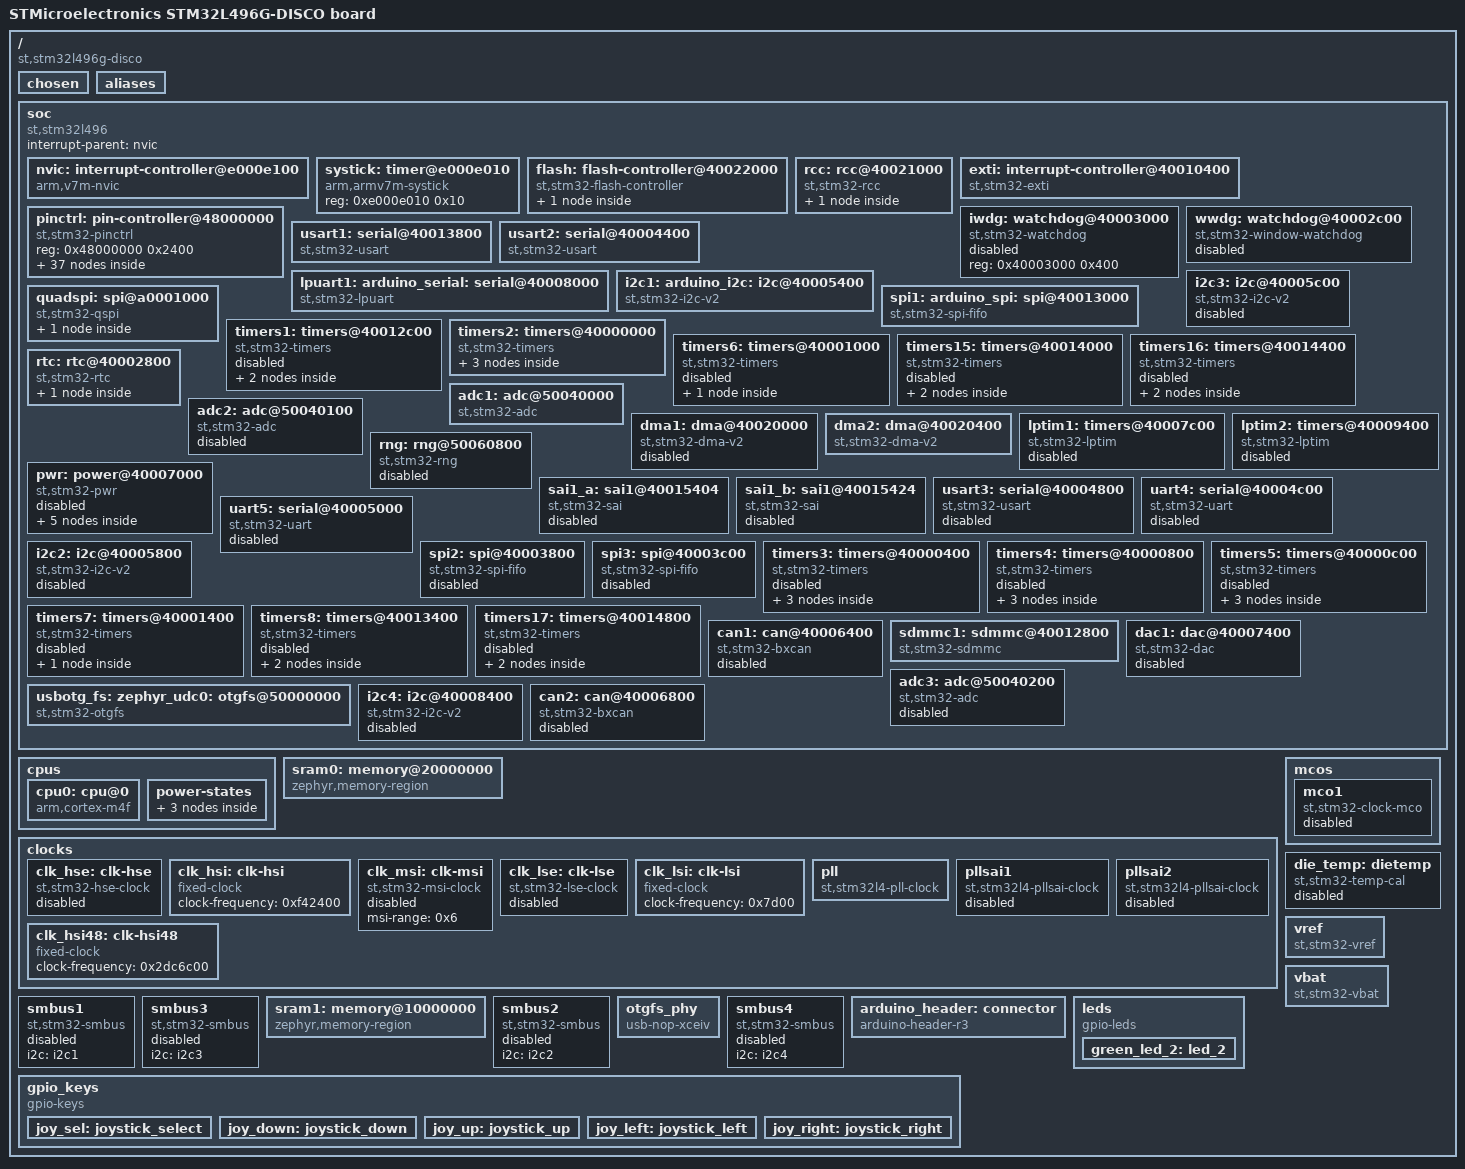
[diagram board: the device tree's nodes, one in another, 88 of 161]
/dts-v1/;

/* node '/' defined in zephyr/dts/common/skeleton.dtsi:9 */
/ {
	#address-cells = < 0x1 >;                            /* in zephyr/dts/common/skeleton.dtsi:10 */
	#size-cells = < 0x1 >;                               /* in zephyr/dts/common/skeleton.dtsi:11 */
	model = "STMicroelectronics STM32L496G-DISCO board"; /* in zephyr/boards/st/stm32l496g_disco/stm32l496g_disco.dts:14 */
	compatible = "st,stm32l496g-disco";                  /* in zephyr/boards/st/stm32l496g_disco/stm32l496g_disco.dts:15 */

	/* node '/chosen' defined in zephyr/dts/common/skeleton.dtsi:13 */
	chosen {
		zephyr,entropy = &rng;                /* in zephyr/dts/arm/st/l4/stm32l4.dtsi:26 */
		zephyr,console = &usart2;             /* in zephyr/boards/st/stm32l496g_disco/stm32l496g_disco.dts:18 */
		zephyr,shell-uart = &usart2;          /* in zephyr/boards/st/stm32l496g_disco/stm32l496g_disco.dts:19 */
		zephyr,sram = &sram0;                 /* in zephyr/boards/st/stm32l496g_disco/stm32l496g_disco.dts:20 */
		zephyr,flash = &flash0;               /* in zephyr/boards/st/stm32l496g_disco/stm32l496g_disco.dts:21 */
		zephyr,flash-controller = &mx25r6435; /* in zephyr/boards/st/stm32l496g_disco/stm32l496g_disco.dts:22 */
	};

	/* node '/aliases' defined in zephyr/dts/common/skeleton.dtsi:15 */
	aliases {
		led0 = &green_led_2;  /* in zephyr/boards/st/stm32l496g_disco/stm32l496g_disco.dts:69 */
		sw0 = &joy_sel;       /* in zephyr/boards/st/stm32l496g_disco/stm32l496g_disco.dts:70 */
		sw1 = &joy_down;      /* in zephyr/boards/st/stm32l496g_disco/stm32l496g_disco.dts:71 */
		sw2 = &joy_right;     /* in zephyr/boards/st/stm32l496g_disco/stm32l496g_disco.dts:72 */
		sw3 = &joy_up;        /* in zephyr/boards/st/stm32l496g_disco/stm32l496g_disco.dts:73 */
		sw4 = &joy_left;      /* in zephyr/boards/st/stm32l496g_disco/stm32l496g_disco.dts:74 */
		volt-sensor0 = &vref; /* in zephyr/boards/st/stm32l496g_disco/stm32l496g_disco.dts:75 */
		volt-sensor1 = &vbat; /* in zephyr/boards/st/stm32l496g_disco/stm32l496g_disco.dts:76 */
	};

	/* node '/soc' defined in zephyr/dts/arm/armv7-m.dtsi:6 */
	soc {
		#address-cells = < 0x1 >;     /* in zephyr/dts/arm/armv7-m.dtsi:7 */
		#size-cells = < 0x1 >;        /* in zephyr/dts/arm/armv7-m.dtsi:8 */
		interrupt-parent = < &nvic >; /* in zephyr/dts/arm/armv7-m.dtsi:10 */
		ranges;                       /* in zephyr/dts/arm/armv7-m.dtsi:11 */
		compatible = "st,stm32l496",
		             "st,stm32l4",
		             "simple-bus";    /* in zephyr/dts/arm/st/l4/stm32l496.dtsi:20 */

		/* node '/soc/interrupt-controller@e000e100' defined in zephyr/dts/arm/armv7-m.dtsi:13 */
		nvic: interrupt-controller@e000e100 {
			#address-cells = < 0x1 >;            /* in zephyr/dts/arm/armv7-m.dtsi:14 */
			compatible = "arm,v7m-nvic";         /* in zephyr/dts/arm/armv7-m.dtsi:15 */
			reg = < 0xe000e100 0xc00 >;          /* in zephyr/dts/arm/armv7-m.dtsi:16 */
			interrupt-controller;                /* in zephyr/dts/arm/armv7-m.dtsi:17 */
			#interrupt-cells = < 0x2 >;          /* in zephyr/dts/arm/armv7-m.dtsi:18 */
			arm,num-irq-priority-bits = < 0x4 >; /* in zephyr/dts/arm/st/l4/stm32l4.dtsi:596 */
			phandle = < 0x1 >;                   /* in zephyr/dts/arm/armv7-m.dtsi:10 */
		};

		/* node '/soc/timer@e000e010' defined in zephyr/dts/arm/armv7-m.dtsi:21 */
		systick: timer@e000e010 {
			compatible = "arm,armv7m-systick"; /* in zephyr/dts/arm/armv7-m.dtsi:22 */
			reg = < 0xe000e010 0x10 >;         /* in zephyr/dts/arm/armv7-m.dtsi:23 */
		};

		/* node '/soc/flash-controller@40022000' defined in zephyr/dts/arm/st/l4/stm32l4.dtsi:127 */
		flash: flash-controller@40022000 {
			compatible = "st,stm32-flash-controller",
			             "st,stm32l4-flash-controller"; /* in zephyr/dts/arm/st/l4/stm32l4.dtsi:128 */
			reg = < 0x40022000 0x400 >;                 /* in zephyr/dts/arm/st/l4/stm32l4.dtsi:129 */
			interrupts = < 0x4 0x0 >;                   /* in zephyr/dts/arm/st/l4/stm32l4.dtsi:130 */
			clocks = < &rcc 0x48 0x100 >;               /* in zephyr/dts/arm/st/l4/stm32l4.dtsi:131 */
			#address-cells = < 0x1 >;                   /* in zephyr/dts/arm/st/l4/stm32l4.dtsi:133 */
			#size-cells = < 0x1 >;                      /* in zephyr/dts/arm/st/l4/stm32l4.dtsi:134 */

			/* node '/soc/flash-controller@40022000/flash@8000000' defined in zephyr/dts/arm/st/l4/stm32l4.dtsi:136 */
			flash0: flash@8000000 {
				compatible = "st,stm32-nv-flash",
				             "soc-nv-flash";      /* in zephyr/dts/arm/st/l4/stm32l4.dtsi:137 */
				write-block-size = < 0x8 >;       /* in zephyr/dts/arm/st/l4/stm32l4.dtsi:139 */
				erase-block-size = < 0x800 >;     /* in zephyr/dts/arm/st/l4/stm32l4.dtsi:140 */
				max-erase-time = < 0x19 >;        /* in zephyr/dts/arm/st/l4/stm32l4.dtsi:142 */
				reg = < 0x8000000 0x100000 >;     /* in zephyr/dts/arm/st/l4/stm32l496Xg.dtsi:20 */
			};
		};

		/* node '/soc/rcc@40021000' defined in zephyr/dts/arm/st/l4/stm32l4.dtsi:146 */
		rcc: rcc@40021000 {
			compatible = "st,stm32-rcc";     /* in zephyr/dts/arm/st/l4/stm32l4.dtsi:147 */
			#clock-cells = < 0x2 >;          /* in zephyr/dts/arm/st/l4/stm32l4.dtsi:148 */
			reg = < 0x40021000 0x400 >;      /* in zephyr/dts/arm/st/l4/stm32l4.dtsi:149 */
			clocks = < &pll >;               /* in zephyr/boards/st/stm32l496g_disco/stm32l496g_disco.dts:103 */
			clock-frequency = < 0x4c4b400 >; /* in zephyr/boards/st/stm32l496g_disco/stm32l496g_disco.dts:104 */
			ahb-prescaler = < 0x1 >;         /* in zephyr/boards/st/stm32l496g_disco/stm32l496g_disco.dts:105 */
			apb1-prescaler = < 0x1 >;        /* in zephyr/boards/st/stm32l496g_disco/stm32l496g_disco.dts:106 */
			apb2-prescaler = < 0x1 >;        /* in zephyr/boards/st/stm32l496g_disco/stm32l496g_disco.dts:107 */
			phandle = < 0x2 >;               /* in zephyr/dts/arm/st/l4/stm32l4.dtsi:131 */

			/* node '/soc/rcc@40021000/reset-controller' defined in zephyr/dts/arm/st/l4/stm32l4.dtsi:151 */
			rctl: reset-controller {
				compatible = "st,stm32-rcc-rctl"; /* in zephyr/dts/arm/st/l4/stm32l4.dtsi:152 */
				#reset-cells = < 0x1 >;           /* in zephyr/dts/arm/st/l4/stm32l4.dtsi:153 */
				phandle = < 0x4 >;                /* in zephyr/dts/arm/st/l4/stm32l4.dtsi:230 */
			};
		};

		/* node '/soc/interrupt-controller@40010400' defined in zephyr/dts/arm/st/l4/stm32l4.dtsi:157 */
		exti: interrupt-controller@40010400 {
			compatible = "st,stm32-exti";  /* in zephyr/dts/arm/st/l4/stm32l4.dtsi:158 */
			interrupt-controller;          /* in zephyr/dts/arm/st/l4/stm32l4.dtsi:159 */
			#interrupt-cells = < 0x1 >;    /* in zephyr/dts/arm/st/l4/stm32l4.dtsi:160 */
			#address-cells = < 0x0 >;      /* in zephyr/dts/arm/st/l4/stm32l4.dtsi:161 */
			reg = < 0x40010400 0x400 >;    /* in zephyr/dts/arm/st/l4/stm32l4.dtsi:162 */
			clocks = < &rcc 0x60 0x1 >;    /* in zephyr/dts/arm/st/l4/stm32l4.dtsi:163 */
			num-lines = < 0x40 >;          /* in zephyr/dts/arm/st/l4/stm32l4.dtsi:164 */
			interrupts = < 0x6 0x0 >,
			             < 0x7 0x0 >,
			             < 0x8 0x0 >,
			             < 0x9 0x0 >,
			             < 0xa 0x0 >,
			             < 0x17 0x0 >,
			             < 0x28 0x0 >;     /* in zephyr/dts/arm/st/l4/stm32l4.dtsi:165 */
			interrupt-names = "line0",
			                  "line1",
			                  "line2",
			                  "line3",
			                  "line4",
			                  "line5-9",
			                  "line10-15"; /* in zephyr/dts/arm/st/l4/stm32l4.dtsi:167 */
			line-ranges = < 0x0 0x1 >,
			              < 0x1 0x1 >,
			              < 0x2 0x1 >,
			              < 0x3 0x1 >,
			              < 0x4 0x1 >,
			              < 0x5 0x5 >,
			              < 0xa 0x6 >;     /* in zephyr/dts/arm/st/l4/stm32l4.dtsi:169 */
		};

		/* node '/soc/pin-controller@48000000' defined in zephyr/dts/arm/st/l4/stm32l4.dtsi:173 */
		pinctrl: pin-controller@48000000 {
			compatible = "st,stm32-pinctrl"; /* in zephyr/dts/arm/st/l4/stm32l4.dtsi:174 */
			#address-cells = < 0x1 >;        /* in zephyr/dts/arm/st/l4/stm32l4.dtsi:175 */
			#size-cells = < 0x1 >;           /* in zephyr/dts/arm/st/l4/stm32l4.dtsi:176 */
			reg = < 0x48000000 0x2400 >;     /* in zephyr/dts/arm/st/l4/stm32l496.dtsi:40 */

			/* node '/soc/pin-controller@48000000/gpio@48000000' defined in zephyr/dts/arm/st/l4/stm32l4.dtsi:179 */
			gpioa: gpio@48000000 {
				compatible = "st,stm32-gpio"; /* in zephyr/dts/arm/st/l4/stm32l4.dtsi:180 */
				gpio-controller;              /* in zephyr/dts/arm/st/l4/stm32l4.dtsi:181 */
				#gpio-cells = < 0x2 >;        /* in zephyr/dts/arm/st/l4/stm32l4.dtsi:182 */
				reg = < 0x48000000 0x400 >;   /* in zephyr/dts/arm/st/l4/stm32l4.dtsi:183 */
				clocks = < &rcc 0x4c 0x1 >;   /* in zephyr/dts/arm/st/l4/stm32l4.dtsi:184 */
				phandle = < 0x17 >;           /* in zephyr/boards/st/stm32l496g_disco/stm32l496g_disco.dts:151 */
			};

			/* node '/soc/pin-controller@48000000/gpio@48000400' defined in zephyr/dts/arm/st/l4/stm32l4.dtsi:187 */
			gpiob: gpio@48000400 {
				compatible = "st,stm32-gpio"; /* in zephyr/dts/arm/st/l4/stm32l4.dtsi:188 */
				gpio-controller;              /* in zephyr/dts/arm/st/l4/stm32l4.dtsi:189 */
				#gpio-cells = < 0x2 >;        /* in zephyr/dts/arm/st/l4/stm32l4.dtsi:190 */
				reg = < 0x48000400 0x400 >;   /* in zephyr/dts/arm/st/l4/stm32l4.dtsi:191 */
				clocks = < &rcc 0x4c 0x2 >;   /* in zephyr/dts/arm/st/l4/stm32l4.dtsi:192 */
				phandle = < 0x32 >;           /* in zephyr/boards/st/stm32l496g_disco/arduino_r3_connector.dtsi:15 */
			};

			/* node '/soc/pin-controller@48000000/gpio@48000800' defined in zephyr/dts/arm/st/l4/stm32l4.dtsi:195 */
			gpioc: gpio@48000800 {
				compatible = "st,stm32-gpio"; /* in zephyr/dts/arm/st/l4/stm32l4.dtsi:196 */
				gpio-controller;              /* in zephyr/dts/arm/st/l4/stm32l4.dtsi:197 */
				#gpio-cells = < 0x2 >;        /* in zephyr/dts/arm/st/l4/stm32l4.dtsi:198 */
				reg = < 0x48000800 0x400 >;   /* in zephyr/dts/arm/st/l4/stm32l4.dtsi:199 */
				clocks = < &rcc 0x4c 0x4 >;   /* in zephyr/dts/arm/st/l4/stm32l4.dtsi:200 */
				phandle = < 0x2d >;           /* in zephyr/boards/st/stm32l496g_disco/arduino_r3_connector.dtsi:15 */
			};

			/* node '/soc/pin-controller@48000000/gpio@48001c00' defined in zephyr/dts/arm/st/l4/stm32l4.dtsi:203 */
			gpioh: gpio@48001c00 {
				compatible = "st,stm32-gpio"; /* in zephyr/dts/arm/st/l4/stm32l4.dtsi:204 */
				gpio-controller;              /* in zephyr/dts/arm/st/l4/stm32l4.dtsi:205 */
				#gpio-cells = < 0x2 >;        /* in zephyr/dts/arm/st/l4/stm32l4.dtsi:206 */
				reg = < 0x48001c00 0x400 >;   /* in zephyr/dts/arm/st/l4/stm32l4.dtsi:207 */
				clocks = < &rcc 0x4c 0x80 >;  /* in zephyr/dts/arm/st/l4/stm32l4.dtsi:208 */
				phandle = < 0x30 >;           /* in zephyr/boards/st/stm32l496g_disco/arduino_r3_connector.dtsi:15 */
			};

			/* node '/soc/pin-controller@48000000/gpio@48000c00' defined in zephyr/dts/arm/st/l4/stm32l471.dtsi:29 */
			gpiod: gpio@48000c00 {
				compatible = "st,stm32-gpio"; /* in zephyr/dts/arm/st/l4/stm32l471.dtsi:30 */
				gpio-controller;              /* in zephyr/dts/arm/st/l4/stm32l471.dtsi:31 */
				#gpio-cells = < 0x2 >;        /* in zephyr/dts/arm/st/l4/stm32l471.dtsi:32 */
				reg = < 0x48000c00 0x400 >;   /* in zephyr/dts/arm/st/l4/stm32l471.dtsi:33 */
				clocks = < &rcc 0x4c 0x8 >;   /* in zephyr/dts/arm/st/l4/stm32l471.dtsi:34 */
			};

			/* node '/soc/pin-controller@48000000/gpio@48001000' defined in zephyr/dts/arm/st/l4/stm32l471.dtsi:37 */
			gpioe: gpio@48001000 {
				compatible = "st,stm32-gpio"; /* in zephyr/dts/arm/st/l4/stm32l471.dtsi:38 */
				gpio-controller;              /* in zephyr/dts/arm/st/l4/stm32l471.dtsi:39 */
				#gpio-cells = < 0x2 >;        /* in zephyr/dts/arm/st/l4/stm32l471.dtsi:40 */
				reg = < 0x48001000 0x400 >;   /* in zephyr/dts/arm/st/l4/stm32l471.dtsi:41 */
				clocks = < &rcc 0x4c 0x10 >;  /* in zephyr/dts/arm/st/l4/stm32l471.dtsi:42 */
			};

			/* node '/soc/pin-controller@48000000/gpio@48001400' defined in zephyr/dts/arm/st/l4/stm32l471.dtsi:45 */
			gpiof: gpio@48001400 {
				compatible = "st,stm32-gpio"; /* in zephyr/dts/arm/st/l4/stm32l471.dtsi:46 */
				gpio-controller;              /* in zephyr/dts/arm/st/l4/stm32l471.dtsi:47 */
				#gpio-cells = < 0x2 >;        /* in zephyr/dts/arm/st/l4/stm32l471.dtsi:48 */
				reg = < 0x48001400 0x400 >;   /* in zephyr/dts/arm/st/l4/stm32l471.dtsi:49 */
				clocks = < &rcc 0x4c 0x20 >;  /* in zephyr/dts/arm/st/l4/stm32l471.dtsi:50 */
				phandle = < 0x2e >;           /* in zephyr/boards/st/stm32l496g_disco/arduino_r3_connector.dtsi:15 */
			};

			/* node '/soc/pin-controller@48000000/gpio@48001800' defined in zephyr/dts/arm/st/l4/stm32l471.dtsi:53 */
			gpiog: gpio@48001800 {
				compatible = "st,stm32-gpio"; /* in zephyr/dts/arm/st/l4/stm32l471.dtsi:54 */
				gpio-controller;              /* in zephyr/dts/arm/st/l4/stm32l471.dtsi:55 */
				#gpio-cells = < 0x2 >;        /* in zephyr/dts/arm/st/l4/stm32l471.dtsi:56 */
				reg = < 0x48001800 0x400 >;   /* in zephyr/dts/arm/st/l4/stm32l471.dtsi:57 */
				clocks = < &rcc 0x4c 0x40 >;  /* in zephyr/dts/arm/st/l4/stm32l471.dtsi:58 */
				phandle = < 0x2f >;           /* in zephyr/boards/st/stm32l496g_disco/arduino_r3_connector.dtsi:15 */
			};

			/* node '/soc/pin-controller@48000000/gpio@48002000' defined in zephyr/dts/arm/st/l4/stm32l496.dtsi:42 */
			gpioi: gpio@48002000 {
				compatible = "st,stm32-gpio"; /* in zephyr/dts/arm/st/l4/stm32l496.dtsi:43 */
				gpio-controller;              /* in zephyr/dts/arm/st/l4/stm32l496.dtsi:44 */
				#gpio-cells = < 0x2 >;        /* in zephyr/dts/arm/st/l4/stm32l496.dtsi:45 */
				ngpios = < 0xc >;             /* in zephyr/dts/arm/st/l4/stm32l496.dtsi:46 */
				reg = < 0x48002000 0x400 >;   /* in zephyr/dts/arm/st/l4/stm32l496.dtsi:47 */
				clocks = < &rcc 0x4c 0x100 >; /* in zephyr/dts/arm/st/l4/stm32l496.dtsi:48 */
				phandle = < 0x31 >;           /* in zephyr/boards/st/stm32l496g_disco/arduino_r3_connector.dtsi:15 */
			};

			/* node '/soc/pin-controller@48000000/adc1_in2_pc1' defined in modules/hal/stm32/dts/st/l4/stm32l496a(e-g)ix-pinctrl.dtsi:59 */
			adc1_in2_pc1: adc1_in2_pc1 {
				pinmux = < 0x430 >; /* in modules/hal/stm32/dts/st/l4/stm32l496a(e-g)ix-pinctrl.dtsi:60 */
				phandle = < 0x19 >; /* in zephyr/boards/st/stm32l496g_disco/stm32l496g_disco.dts:171 */
			};

			/* node '/soc/pin-controller@48000000/i2c1_scl_pb8' defined in modules/hal/stm32/dts/st/l4/stm32l496a(e-g)ix-pinctrl.dtsi:1612 */
			i2c1_scl_pb8: i2c1_scl_pb8 {
				pinmux = < 0x304 >; /* in modules/hal/stm32/dts/st/l4/stm32l496a(e-g)ix-pinctrl.dtsi:1613 */
				bias-pull-up;       /* in modules/hal/stm32/dts/st/l4/stm32l496a(e-g)ix-pinctrl.dtsi:1614 */
				drive-open-drain;   /* in modules/hal/stm32/dts/st/l4/stm32l496a(e-g)ix-pinctrl.dtsi:1615 */
				phandle = < 0xb >;  /* in zephyr/boards/st/stm32l496g_disco/stm32l496g_disco.dts:142 */
			};

			/* node '/soc/pin-controller@48000000/i2c1_sda_pb7' defined in modules/hal/stm32/dts/st/l4/stm32l496a(e-g)ix-pinctrl.dtsi:1704 */
			i2c1_sda_pb7: i2c1_sda_pb7 {
				pinmux = < 0x2e4 >; /* in modules/hal/stm32/dts/st/l4/stm32l496a(e-g)ix-pinctrl.dtsi:1705 */
				bias-pull-up;       /* in modules/hal/stm32/dts/st/l4/stm32l496a(e-g)ix-pinctrl.dtsi:1706 */
				drive-open-drain;   /* in modules/hal/stm32/dts/st/l4/stm32l496a(e-g)ix-pinctrl.dtsi:1707 */
				phandle = < 0xc >;  /* in zephyr/boards/st/stm32l496g_disco/stm32l496g_disco.dts:142 */
			};

			/* node '/soc/pin-controller@48000000/quadspi_clk_pa3' defined in modules/hal/stm32/dts/st/l4/stm32l496a(e-g)ix-pinctrl.dtsi:1920 */
			quadspi_clk_pa3: quadspi_clk_pa3 {
				pinmux = < 0x6a >;             /* in modules/hal/stm32/dts/st/l4/stm32l496a(e-g)ix-pinctrl.dtsi:1921 */
				slew-rate = "very-high-speed"; /* in modules/hal/stm32/dts/st/l4/stm32l496a(e-g)ix-pinctrl.dtsi:1922 */
				phandle = < 0x12 >;            /* in zephyr/boards/st/stm32l496g_disco/stm32l496g_disco.dts:198 */
			};

			/* node '/soc/pin-controller@48000000/quadspi_bk1_io3_pa6' defined in modules/hal/stm32/dts/st/l4/stm32l496a(e-g)ix-pinctrl.dtsi:1925 */
			quadspi_bk1_io3_pa6: quadspi_bk1_io3_pa6 {
				pinmux = < 0xca >;             /* in modules/hal/stm32/dts/st/l4/stm32l496a(e-g)ix-pinctrl.dtsi:1926 */
				slew-rate = "very-high-speed"; /* in modules/hal/stm32/dts/st/l4/stm32l496a(e-g)ix-pinctrl.dtsi:1927 */
				phandle = < 0x10 >;            /* in zephyr/boards/st/stm32l496g_disco/stm32l496g_disco.dts:198 */
			};

			/* node '/soc/pin-controller@48000000/quadspi_bk1_io2_pa7' defined in modules/hal/stm32/dts/st/l4/stm32l496a(e-g)ix-pinctrl.dtsi:1930 */
			quadspi_bk1_io2_pa7: quadspi_bk1_io2_pa7 {
				pinmux = < 0xea >;             /* in modules/hal/stm32/dts/st/l4/stm32l496a(e-g)ix-pinctrl.dtsi:1931 */
				slew-rate = "very-high-speed"; /* in modules/hal/stm32/dts/st/l4/stm32l496a(e-g)ix-pinctrl.dtsi:1932 */
				phandle = < 0xf >;             /* in zephyr/boards/st/stm32l496g_disco/stm32l496g_disco.dts:198 */
			};

			/* node '/soc/pin-controller@48000000/quadspi_bk1_io1_pb0' defined in modules/hal/stm32/dts/st/l4/stm32l496a(e-g)ix-pinctrl.dtsi:1935 */
			quadspi_bk1_io1_pb0: quadspi_bk1_io1_pb0 {
				pinmux = < 0x20a >;            /* in modules/hal/stm32/dts/st/l4/stm32l496a(e-g)ix-pinctrl.dtsi:1936 */
				slew-rate = "very-high-speed"; /* in modules/hal/stm32/dts/st/l4/stm32l496a(e-g)ix-pinctrl.dtsi:1937 */
				phandle = < 0xe >;             /* in zephyr/boards/st/stm32l496g_disco/stm32l496g_disco.dts:198 */
			};

			/* node '/soc/pin-controller@48000000/quadspi_bk1_io0_pb1' defined in modules/hal/stm32/dts/st/l4/stm32l496a(e-g)ix-pinctrl.dtsi:1940 */
			quadspi_bk1_io0_pb1: quadspi_bk1_io0_pb1 {
				pinmux = < 0x22a >;            /* in modules/hal/stm32/dts/st/l4/stm32l496a(e-g)ix-pinctrl.dtsi:1941 */
				slew-rate = "very-high-speed"; /* in modules/hal/stm32/dts/st/l4/stm32l496a(e-g)ix-pinctrl.dtsi:1942 */
				phandle = < 0xd >;             /* in zephyr/boards/st/stm32l496g_disco/stm32l496g_disco.dts:198 */
			};

			/* node '/soc/pin-controller@48000000/quadspi_bk1_ncs_pb11' defined in modules/hal/stm32/dts/st/l4/stm32l496a(e-g)ix-pinctrl.dtsi:1950 */
			quadspi_bk1_ncs_pb11: quadspi_bk1_ncs_pb11 {
				pinmux = < 0x36a >;            /* in modules/hal/stm32/dts/st/l4/stm32l496a(e-g)ix-pinctrl.dtsi:1951 */
				slew-rate = "very-high-speed"; /* in modules/hal/stm32/dts/st/l4/stm32l496a(e-g)ix-pinctrl.dtsi:1952 */
				phandle = < 0x11 >;            /* in zephyr/boards/st/stm32l496g_disco/stm32l496g_disco.dts:198 */
			};

			/* node '/soc/pin-controller@48000000/sdmmc1_d0_pc8' defined in modules/hal/stm32/dts/st/l4/stm32l496a(e-g)ix-pinctrl.dtsi:2297 */
			sdmmc1_d0_pc8: sdmmc1_d0_pc8 {
				pinmux = < 0x50c >;            /* in modules/hal/stm32/dts/st/l4/stm32l496a(e-g)ix-pinctrl.dtsi:2298 */
				bias-pull-up;                  /* in modules/hal/stm32/dts/st/l4/stm32l496a(e-g)ix-pinctrl.dtsi:2299 */
				slew-rate = "very-high-speed"; /* in modules/hal/stm32/dts/st/l4/stm32l496a(e-g)ix-pinctrl.dtsi:2300 */
				phandle = < 0x1a >;            /* in zephyr/boards/st/stm32l496g_disco/stm32l496g_disco.dts:162 */
			};

			/* node '/soc/pin-controller@48000000/sdmmc1_d1_pc9' defined in modules/hal/stm32/dts/st/l4/stm32l496a(e-g)ix-pinctrl.dtsi:2303 */
			sdmmc1_d1_pc9: sdmmc1_d1_pc9 {
				pinmux = < 0x52c >;            /* in modules/hal/stm32/dts/st/l4/stm32l496a(e-g)ix-pinctrl.dtsi:2304 */
				bias-pull-up;                  /* in modules/hal/stm32/dts/st/l4/stm32l496a(e-g)ix-pinctrl.dtsi:2305 */
				slew-rate = "very-high-speed"; /* in modules/hal/stm32/dts/st/l4/stm32l496a(e-g)ix-pinctrl.dtsi:2306 */
				phandle = < 0x1b >;            /* in zephyr/boards/st/stm32l496g_disco/stm32l496g_disco.dts:162 */
			};

			/* node '/soc/pin-controller@48000000/sdmmc1_d2_pc10' defined in modules/hal/stm32/dts/st/l4/stm32l496a(e-g)ix-pinctrl.dtsi:2309 */
			sdmmc1_d2_pc10: sdmmc1_d2_pc10 {
				pinmux = < 0x54c >;            /* in modules/hal/stm32/dts/st/l4/stm32l496a(e-g)ix-pinctrl.dtsi:2310 */
				bias-pull-up;                  /* in modules/hal/stm32/dts/st/l4/stm32l496a(e-g)ix-pinctrl.dtsi:2311 */
				slew-rate = "very-high-speed"; /* in modules/hal/stm32/dts/st/l4/stm32l496a(e-g)ix-pinctrl.dtsi:2312 */
				phandle = < 0x1c >;            /* in zephyr/boards/st/stm32l496g_disco/stm32l496g_disco.dts:162 */
			};

			/* node '/soc/pin-controller@48000000/sdmmc1_d3_pc11' defined in modules/hal/stm32/dts/st/l4/stm32l496a(e-g)ix-pinctrl.dtsi:2315 */
			sdmmc1_d3_pc11: sdmmc1_d3_pc11 {
				pinmux = < 0x56c >;            /* in modules/hal/stm32/dts/st/l4/stm32l496a(e-g)ix-pinctrl.dtsi:2316 */
				bias-pull-up;                  /* in modules/hal/stm32/dts/st/l4/stm32l496a(e-g)ix-pinctrl.dtsi:2317 */
				slew-rate = "very-high-speed"; /* in modules/hal/stm32/dts/st/l4/stm32l496a(e-g)ix-pinctrl.dtsi:2318 */
				phandle = < 0x1d >;            /* in zephyr/boards/st/stm32l496g_disco/stm32l496g_disco.dts:162 */
			};

			/* node '/soc/pin-controller@48000000/sdmmc1_ck_pc12' defined in modules/hal/stm32/dts/st/l4/stm32l496a(e-g)ix-pinctrl.dtsi:2321 */
			sdmmc1_ck_pc12: sdmmc1_ck_pc12 {
				pinmux = < 0x58c >;            /* in modules/hal/stm32/dts/st/l4/stm32l496a(e-g)ix-pinctrl.dtsi:2322 */
				bias-pull-up;                  /* in modules/hal/stm32/dts/st/l4/stm32l496a(e-g)ix-pinctrl.dtsi:2323 */
				slew-rate = "very-high-speed"; /* in modules/hal/stm32/dts/st/l4/stm32l496a(e-g)ix-pinctrl.dtsi:2324 */
				phandle = < 0x1e >;            /* in zephyr/boards/st/stm32l496g_disco/stm32l496g_disco.dts:162 */
			};

			/* node '/soc/pin-controller@48000000/sdmmc1_cmd_pd2' defined in modules/hal/stm32/dts/st/l4/stm32l496a(e-g)ix-pinctrl.dtsi:2327 */
			sdmmc1_cmd_pd2: sdmmc1_cmd_pd2 {
				pinmux = < 0x64c >;            /* in modules/hal/stm32/dts/st/l4/stm32l496a(e-g)ix-pinctrl.dtsi:2328 */
				bias-pull-up;                  /* in modules/hal/stm32/dts/st/l4/stm32l496a(e-g)ix-pinctrl.dtsi:2329 */
				slew-rate = "very-high-speed"; /* in modules/hal/stm32/dts/st/l4/stm32l496a(e-g)ix-pinctrl.dtsi:2330 */
				phandle = < 0x1f >;            /* in zephyr/boards/st/stm32l496g_disco/stm32l496g_disco.dts:162 */
			};

			/* node '/soc/pin-controller@48000000/spi1_miso_pb4' defined in modules/hal/stm32/dts/st/l4/stm32l496a(e-g)ix-pinctrl.dtsi:2345 */
			spi1_miso_pb4: spi1_miso_pb4 {
				pinmux = < 0x285 >; /* in modules/hal/stm32/dts/st/l4/stm32l496a(e-g)ix-pinctrl.dtsi:2346 */
				bias-pull-down;     /* in modules/hal/stm32/dts/st/l4/stm32l496a(e-g)ix-pinctrl.dtsi:2347 */
				phandle = < 0x15 >; /* in zephyr/boards/st/stm32l496g_disco/stm32l496g_disco.dts:149 */
			};

			/* node '/soc/pin-controller@48000000/spi1_mosi_pb5' defined in modules/hal/stm32/dts/st/l4/stm32l496a(e-g)ix-pinctrl.dtsi:2407 */
			spi1_mosi_pb5: spi1_mosi_pb5 {
				pinmux = < 0x2a5 >; /* in modules/hal/stm32/dts/st/l4/stm32l496a(e-g)ix-pinctrl.dtsi:2408 */
				bias-pull-down;     /* in modules/hal/stm32/dts/st/l4/stm32l496a(e-g)ix-pinctrl.dtsi:2409 */
				phandle = < 0x16 >; /* in zephyr/boards/st/stm32l496g_disco/stm32l496g_disco.dts:149 */
			};

			/* node '/soc/pin-controller@48000000/spi1_sck_pa5' defined in modules/hal/stm32/dts/st/l4/stm32l496a(e-g)ix-pinctrl.dtsi:2532 */
			spi1_sck_pa5: spi1_sck_pa5 {
				pinmux = < 0xa5 >;             /* in modules/hal/stm32/dts/st/l4/stm32l496a(e-g)ix-pinctrl.dtsi:2533 */
				bias-pull-down;                /* in modules/hal/stm32/dts/st/l4/stm32l496a(e-g)ix-pinctrl.dtsi:2534 */
				slew-rate = "very-high-speed"; /* in modules/hal/stm32/dts/st/l4/stm32l496a(e-g)ix-pinctrl.dtsi:2535 */
				phandle = < 0x14 >;            /* in zephyr/boards/st/stm32l496g_disco/stm32l496g_disco.dts:149 */
			};

			/* node '/soc/pin-controller@48000000/tim2_ch1_pa0' defined in modules/hal/stm32/dts/st/l4/stm32l496a(e-g)ix-pinctrl.dtsi:2742 */
			tim2_ch1_pa0: tim2_ch1_pa0 {
				pinmux = < 0x1 >;   /* in modules/hal/stm32/dts/st/l4/stm32l496a(e-g)ix-pinctrl.dtsi:2743 */
				phandle = < 0x18 >; /* in zephyr/boards/st/stm32l496g_disco/stm32l496g_disco.dts:136 */
			};

			/* node '/soc/pin-controller@48000000/lpuart1_rx_pg8' defined in modules/hal/stm32/dts/st/l4/stm32l496a(e-g)ix-pinctrl.dtsi:3419 */
			lpuart1_rx_pg8: lpuart1_rx_pg8 {
				pinmux = < 0xd08 >; /* in modules/hal/stm32/dts/st/l4/stm32l496a(e-g)ix-pinctrl.dtsi:3420 */
				phandle = < 0xa >;  /* in zephyr/boards/st/stm32l496g_disco/stm32l496g_disco.dts:125 */
			};

			/* node '/soc/pin-controller@48000000/usart1_rx_pg10' defined in modules/hal/stm32/dts/st/l4/stm32l496a(e-g)ix-pinctrl.dtsi:3423 */
			usart1_rx_pg10: usart1_rx_pg10 {
				pinmux = < 0xd47 >; /* in modules/hal/stm32/dts/st/l4/stm32l496a(e-g)ix-pinctrl.dtsi:3424 */
				phandle = < 0x6 >;  /* in zephyr/boards/st/stm32l496g_disco/stm32l496g_disco.dts:111 */
			};

			/* node '/soc/pin-controller@48000000/usart2_rx_pd6' defined in modules/hal/stm32/dts/st/l4/stm32l496a(e-g)ix-pinctrl.dtsi:3435 */
			usart2_rx_pd6: usart2_rx_pd6 {
				pinmux = < 0x6c7 >; /* in modules/hal/stm32/dts/st/l4/stm32l496a(e-g)ix-pinctrl.dtsi:3436 */
				phandle = < 0x8 >;  /* in zephyr/boards/st/stm32l496g_disco/stm32l496g_disco.dts:118 */
			};

			/* node '/soc/pin-controller@48000000/usart1_tx_pb6' defined in modules/hal/stm32/dts/st/l4/stm32l496a(e-g)ix-pinctrl.dtsi:3479 */
			usart1_tx_pb6: usart1_tx_pb6 {
				pinmux = < 0x2c7 >; /* in modules/hal/stm32/dts/st/l4/stm32l496a(e-g)ix-pinctrl.dtsi:3480 */
				bias-pull-up;       /* in modules/hal/stm32/dts/st/l4/stm32l496a(e-g)ix-pinctrl.dtsi:3481 */
				phandle = < 0x5 >;  /* in zephyr/boards/st/stm32l496g_disco/stm32l496g_disco.dts:111 */
			};

			/* node '/soc/pin-controller@48000000/lpuart1_tx_pg7' defined in modules/hal/stm32/dts/st/l4/stm32l496a(e-g)ix-pinctrl.dtsi:3494 */
			lpuart1_tx_pg7: lpuart1_tx_pg7 {
				pinmux = < 0xce8 >; /* in modules/hal/stm32/dts/st/l4/stm32l496a(e-g)ix-pinctrl.dtsi:3495 */
				bias-pull-up;       /* in modules/hal/stm32/dts/st/l4/stm32l496a(e-g)ix-pinctrl.dtsi:3496 */
				phandle = < 0x9 >;  /* in zephyr/boards/st/stm32l496g_disco/stm32l496g_disco.dts:125 */
			};

			/* node '/soc/pin-controller@48000000/usart2_tx_pa2' defined in modules/hal/stm32/dts/st/l4/stm32l496a(e-g)ix-pinctrl.dtsi:3504 */
			usart2_tx_pa2: usart2_tx_pa2 {
				pinmux = < 0x47 >; /* in modules/hal/stm32/dts/st/l4/stm32l496a(e-g)ix-pinctrl.dtsi:3505 */
				bias-pull-up;      /* in modules/hal/stm32/dts/st/l4/stm32l496a(e-g)ix-pinctrl.dtsi:3506 */
				phandle = < 0x7 >; /* in zephyr/boards/st/stm32l496g_disco/stm32l496g_disco.dts:118 */
			};

			/* node '/soc/pin-controller@48000000/usb_otg_fs_id_pa10' defined in modules/hal/stm32/dts/st/l4/stm32l496a(e-g)ix-pinctrl.dtsi:3559 */
			usb_otg_fs_id_pa10: usb_otg_fs_id_pa10 {
				pinmux = < 0x14a >; /* in modules/hal/stm32/dts/st/l4/stm32l496a(e-g)ix-pinctrl.dtsi:3560 */
				phandle = < 0x23 >; /* in zephyr/boards/st/stm32l496g_disco/stm32l496g_disco.dts:179 */
			};

			/* node '/soc/pin-controller@48000000/usb_otg_fs_dm_pa11' defined in modules/hal/stm32/dts/st/l4/stm32l496a(e-g)ix-pinctrl.dtsi:3563 */
			usb_otg_fs_dm_pa11: usb_otg_fs_dm_pa11 {
				pinmux = < 0x16a >; /* in modules/hal/stm32/dts/st/l4/stm32l496a(e-g)ix-pinctrl.dtsi:3564 */
				phandle = < 0x21 >; /* in zephyr/boards/st/stm32l496g_disco/stm32l496g_disco.dts:179 */
			};

			/* node '/soc/pin-controller@48000000/usb_otg_fs_dp_pa12' defined in modules/hal/stm32/dts/st/l4/stm32l496a(e-g)ix-pinctrl.dtsi:3567 */
			usb_otg_fs_dp_pa12: usb_otg_fs_dp_pa12 {
				pinmux = < 0x18a >; /* in modules/hal/stm32/dts/st/l4/stm32l496a(e-g)ix-pinctrl.dtsi:3568 */
				phandle = < 0x22 >; /* in zephyr/boards/st/stm32l496g_disco/stm32l496g_disco.dts:179 */
			};
		};

		/* node '/soc/watchdog@40003000' defined in zephyr/dts/arm/st/l4/stm32l4.dtsi:212 */
		iwdg: watchdog@40003000 {
			compatible = "st,stm32-watchdog"; /* in zephyr/dts/arm/st/l4/stm32l4.dtsi:213 */
			reg = < 0x40003000 0x400 >;       /* in zephyr/dts/arm/st/l4/stm32l4.dtsi:214 */
			status = "disabled";              /* in zephyr/dts/arm/st/l4/stm32l4.dtsi:215 */
		};

		/* node '/soc/watchdog@40002c00' defined in zephyr/dts/arm/st/l4/stm32l4.dtsi:218 */
		wwdg: watchdog@40002c00 {
			compatible = "st,stm32-window-watchdog"; /* in zephyr/dts/arm/st/l4/stm32l4.dtsi:219 */
			reg = < 0x40002c00 0x400 >;              /* in zephyr/dts/arm/st/l4/stm32l4.dtsi:220 */
			clocks = < &rcc 0x58 0x800 >;            /* in zephyr/dts/arm/st/l4/stm32l4.dtsi:221 */
			interrupts = < 0x0 0x7 >;                /* in zephyr/dts/arm/st/l4/stm32l4.dtsi:222 */
			status = "disabled";                     /* in zephyr/dts/arm/st/l4/stm32l4.dtsi:223 */
		};

		/* node '/soc/serial@40013800' defined in zephyr/dts/arm/st/l4/stm32l4.dtsi:226 */
		usart1: serial@40013800 {
			compatible = "st,stm32-usart",
			             "st,stm32-uart";                   /* in zephyr/dts/arm/st/l4/stm32l4.dtsi:227 */
			reg = < 0x40013800 0x400 >;                     /* in zephyr/dts/arm/st/l4/stm32l4.dtsi:228 */
			clocks = < &rcc 0x60 0x4000 >;                  /* in zephyr/dts/arm/st/l4/stm32l4.dtsi:229 */
			resets = < &rctl 0x80e >;                       /* in zephyr/dts/arm/st/l4/stm32l4.dtsi:230 */
			interrupts = < 0x25 0x0 >;                      /* in zephyr/dts/arm/st/l4/stm32l4.dtsi:231 */
			pinctrl-0 = < &usart1_tx_pb6 &usart1_rx_pg10 >; /* in zephyr/boards/st/stm32l496g_disco/stm32l496g_disco.dts:111 */
			pinctrl-names = "default";                      /* in zephyr/boards/st/stm32l496g_disco/stm32l496g_disco.dts:112 */
			current-speed = < 0x1c200 >;                    /* in zephyr/boards/st/stm32l496g_disco/stm32l496g_disco.dts:113 */
			status = "okay";                                /* in zephyr/boards/st/stm32l496g_disco/stm32l496g_disco.dts:114 */
		};

		/* node '/soc/serial@40004400' defined in zephyr/dts/arm/st/l4/stm32l4.dtsi:235 */
		usart2: serial@40004400 {
			compatible = "st,stm32-usart",
			             "st,stm32-uart";                  /* in zephyr/dts/arm/st/l4/stm32l4.dtsi:236 */
			reg = < 0x40004400 0x400 >;                    /* in zephyr/dts/arm/st/l4/stm32l4.dtsi:237 */
			clocks = < &rcc 0x58 0x20000 >;                /* in zephyr/dts/arm/st/l4/stm32l4.dtsi:238 */
			resets = < &rctl 0x711 >;                      /* in zephyr/dts/arm/st/l4/stm32l4.dtsi:239 */
			interrupts = < 0x26 0x0 >;                     /* in zephyr/dts/arm/st/l4/stm32l4.dtsi:240 */
			pinctrl-0 = < &usart2_tx_pa2 &usart2_rx_pd6 >; /* in zephyr/boards/st/stm32l496g_disco/stm32l496g_disco.dts:118 */
			pinctrl-names = "default";                     /* in zephyr/boards/st/stm32l496g_disco/stm32l496g_disco.dts:119 */
			current-speed = < 0x1c200 >;                   /* in zephyr/boards/st/stm32l496g_disco/stm32l496g_disco.dts:120 */
			status = "okay";                               /* in zephyr/boards/st/stm32l496g_disco/stm32l496g_disco.dts:121 */
		};

		/* node '/soc/serial@40008000' defined in zephyr/dts/arm/st/l4/stm32l4.dtsi:244 */
		lpuart1: arduino_serial: serial@40008000 {
			compatible = "st,stm32-lpuart",
			             "st,stm32-uart";                    /* in zephyr/dts/arm/st/l4/stm32l4.dtsi:245 */
			reg = < 0x40008000 0x400 >;                      /* in zephyr/dts/arm/st/l4/stm32l4.dtsi:246 */
			clocks = < &rcc 0x5c 0x1 >;                      /* in zephyr/dts/arm/st/l4/stm32l4.dtsi:247 */
			resets = < &rctl 0x780 >;                        /* in zephyr/dts/arm/st/l4/stm32l4.dtsi:248 */
			interrupts = < 0x46 0x0 >;                       /* in zephyr/dts/arm/st/l4/stm32l4.dtsi:249 */
			pinctrl-0 = < &lpuart1_tx_pg7 &lpuart1_rx_pg8 >; /* in zephyr/boards/st/stm32l496g_disco/stm32l496g_disco.dts:125 */
			pinctrl-names = "default";                       /* in zephyr/boards/st/stm32l496g_disco/stm32l496g_disco.dts:126 */
			current-speed = < 0x1c200 >;                     /* in zephyr/boards/st/stm32l496g_disco/stm32l496g_disco.dts:127 */
			status = "okay";                                 /* in zephyr/boards/st/stm32l496g_disco/stm32l496g_disco.dts:128 */
		};

		/* node '/soc/i2c@40005400' defined in zephyr/dts/arm/st/l4/stm32l4.dtsi:253 */
		i2c1: arduino_i2c: i2c@40005400 {
			compatible = "st,stm32-i2c-v2";              /* in zephyr/dts/arm/st/l4/stm32l4.dtsi:254 */
			#address-cells = < 0x1 >;                    /* in zephyr/dts/arm/st/l4/stm32l4.dtsi:256 */
			#size-cells = < 0x0 >;                       /* in zephyr/dts/arm/st/l4/stm32l4.dtsi:257 */
			reg = < 0x40005400 0x400 >;                  /* in zephyr/dts/arm/st/l4/stm32l4.dtsi:258 */
			clocks = < &rcc 0x58 0x200000 >;             /* in zephyr/dts/arm/st/l4/stm32l4.dtsi:259 */
			interrupts = < 0x1f 0x0 >,
			             < 0x20 0x0 >;                   /* in zephyr/dts/arm/st/l4/stm32l4.dtsi:260 */
			interrupt-names = "event",
			                  "error";                   /* in zephyr/dts/arm/st/l4/stm32l4.dtsi:261 */
			pinctrl-0 = < &i2c1_scl_pb8 &i2c1_sda_pb7 >; /* in zephyr/boards/st/stm32l496g_disco/stm32l496g_disco.dts:142 */
			pinctrl-names = "default";                   /* in zephyr/boards/st/stm32l496g_disco/stm32l496g_disco.dts:143 */
			status = "okay";                             /* in zephyr/boards/st/stm32l496g_disco/stm32l496g_disco.dts:144 */
			clock-frequency = < 0x61a80 >;               /* in zephyr/boards/st/stm32l496g_disco/stm32l496g_disco.dts:145 */
			phandle = < 0x29 >;                          /* in zephyr/dts/arm/st/l4/stm32l4.dtsi:582 */
		};

		/* node '/soc/i2c@40005c00' defined in zephyr/dts/arm/st/l4/stm32l4.dtsi:265 */
		i2c3: i2c@40005c00 {
			compatible = "st,stm32-i2c-v2";  /* in zephyr/dts/arm/st/l4/stm32l4.dtsi:266 */
			clock-frequency = < 0x186a0 >;   /* in zephyr/dts/arm/st/l4/stm32l4.dtsi:267 */
			#address-cells = < 0x1 >;        /* in zephyr/dts/arm/st/l4/stm32l4.dtsi:268 */
			#size-cells = < 0x0 >;           /* in zephyr/dts/arm/st/l4/stm32l4.dtsi:269 */
			reg = < 0x40005c00 0x400 >;      /* in zephyr/dts/arm/st/l4/stm32l4.dtsi:270 */
			clocks = < &rcc 0x58 0x800000 >; /* in zephyr/dts/arm/st/l4/stm32l4.dtsi:271 */
			interrupts = < 0x48 0x0 >,
			             < 0x49 0x0 >;       /* in zephyr/dts/arm/st/l4/stm32l4.dtsi:272 */
			interrupt-names = "event",
			                  "error";       /* in zephyr/dts/arm/st/l4/stm32l4.dtsi:273 */
			status = "disabled";             /* in zephyr/dts/arm/st/l4/stm32l4.dtsi:274 */
			phandle = < 0x2a >;              /* in zephyr/dts/arm/st/l4/stm32l4.dtsi:590 */
		};

		/* node '/soc/spi@a0001000' defined in zephyr/dts/arm/st/l4/stm32l4.dtsi:277 */
		quadspi: spi@a0001000 {
			compatible = "st,stm32-qspi";                                                                     /* in zephyr/dts/arm/st/l4/stm32l4.dtsi:278 */
			#address-cells = < 0x1 >;                                                                         /* in zephyr/dts/arm/st/l4/stm32l4.dtsi:279 */
			#size-cells = < 0x0 >;                                                                            /* in zephyr/dts/arm/st/l4/stm32l4.dtsi:280 */
			reg = < 0xa0001000 0x400 >,
			      < 0x90000000 0x10000000 >;                                                                  /* in zephyr/dts/arm/st/l4/stm32l4.dtsi:281 */
			interrupts = < 0x47 0x0 >;                                                                        /* in zephyr/dts/arm/st/l4/stm32l4.dtsi:282 */
			clocks = < &rcc 0x50 0x100 >;                                                                     /* in zephyr/dts/arm/st/l4/stm32l4.dtsi:283 */
			pinctrl-0 = < &quadspi_bk1_io0_pb1 &quadspi_bk1_io1_pb0 &quadspi_bk1_io2_pa7 &quadspi_bk1_io3_pa6
			              &quadspi_bk1_ncs_pb11 &quadspi_clk_pa3 >;                                           /* in zephyr/boards/st/stm32l496g_disco/stm32l496g_disco.dts:198 */
			pinctrl-names = "default";                                                                        /* in zephyr/boards/st/stm32l496g_disco/stm32l496g_disco.dts:201 */
			dmas = < &dma2 0x7 0x3 0x480 >;                                                                   /* in zephyr/boards/st/stm32l496g_disco/stm32l496g_disco.dts:203 */
			dma-names = "tx_rx";                                                                              /* in zephyr/boards/st/stm32l496g_disco/stm32l496g_disco.dts:204 */
			flash-id = < 0x1 >;                                                                               /* in zephyr/boards/st/stm32l496g_disco/stm32l496g_disco.dts:206 */
			status = "okay";                                                                                  /* in zephyr/boards/st/stm32l496g_disco/stm32l496g_disco.dts:207 */

			/* node '/soc/spi@a0001000/qspi-nor-flash@0' defined in zephyr/boards/st/stm32l496g_disco/stm32l496g_disco.dts:209 */
			mx25r6435: qspi-nor-flash@0 {
				compatible = "st,stm32-qspi-nor";  /* in zephyr/boards/st/stm32l496g_disco/stm32l496g_disco.dts:210 */
				reg = < 0x0 >;                     /* in zephyr/boards/st/stm32l496g_disco/stm32l496g_disco.dts:211 */
				size = < 0x4000000 >;              /* in zephyr/boards/st/stm32l496g_disco/stm32l496g_disco.dts:212 */
				qspi-max-frequency = < 0x7a1200 >; /* in zephyr/boards/st/stm32l496g_disco/stm32l496g_disco.dts:213 */
				cs-high-time = < 0x3 >;            /* in zephyr/boards/st/stm32l496g_disco/stm32l496g_disco.dts:214 */
				status = "okay";                   /* in zephyr/boards/st/stm32l496g_disco/stm32l496g_disco.dts:215 */
				spi-bus-width = < 0x4 >;           /* in zephyr/boards/st/stm32l496g_disco/stm32l496g_disco.dts:216 */
				writeoc = "PP_1_4_4";              /* in zephyr/boards/st/stm32l496g_disco/stm32l496g_disco.dts:217 */
			};
		};

		/* node '/soc/spi@40013000' defined in zephyr/dts/arm/st/l4/stm32l4.dtsi:287 */
		spi1: arduino_spi: spi@40013000 {
			compatible = "st,stm32-spi-fifo",
			             "st,stm32-spi";                                 /* in zephyr/dts/arm/st/l4/stm32l4.dtsi:288 */
			#address-cells = < 0x1 >;                                    /* in zephyr/dts/arm/st/l4/stm32l4.dtsi:289 */
			#size-cells = < 0x0 >;                                       /* in zephyr/dts/arm/st/l4/stm32l4.dtsi:290 */
			reg = < 0x40013000 0x400 >;                                  /* in zephyr/dts/arm/st/l4/stm32l4.dtsi:291 */
			interrupts = < 0x23 0x5 >;                                   /* in zephyr/dts/arm/st/l4/stm32l4.dtsi:292 */
			clocks = < &rcc 0x60 0x1000 >;                               /* in zephyr/dts/arm/st/l4/stm32l4.dtsi:293 */
			pinctrl-0 = < &spi1_sck_pa5 &spi1_miso_pb4 &spi1_mosi_pb5 >; /* in zephyr/boards/st/stm32l496g_disco/stm32l496g_disco.dts:149 */
			pinctrl-names = "default";                                   /* in zephyr/boards/st/stm32l496g_disco/stm32l496g_disco.dts:150 */
			cs-gpios = < &gpioa 0xf 0x11 >;                              /* in zephyr/boards/st/stm32l496g_disco/stm32l496g_disco.dts:151 */
			status = "okay";                                             /* in zephyr/boards/st/stm32l496g_disco/stm32l496g_disco.dts:152 */
		};

		/* node '/soc/timers@40012c00' defined in zephyr/dts/arm/st/l4/stm32l4.dtsi:297 */
		timers1: timers@40012c00 {
			compatible = "st,stm32-timers"; /* in zephyr/dts/arm/st/l4/stm32l4.dtsi:298 */
			reg = < 0x40012c00 0x400 >;     /* in zephyr/dts/arm/st/l4/stm32l4.dtsi:299 */
			clocks = < &rcc 0x60 0x800 >,
			         < &rcc 0x9 0xff >;     /* in zephyr/dts/arm/st/l4/stm32l4.dtsi:300 */
			resets = < &rctl 0x80b >;       /* in zephyr/dts/arm/st/l4/stm32l4.dtsi:302 */
			interrupts = < 0x18 0x0 >,
			             < 0x19 0x0 >,
			             < 0x1a 0x0 >,
			             < 0x1b 0x0 >;      /* in zephyr/dts/arm/st/l4/stm32l4.dtsi:303 */
			interrupt-names = "brk",
			                  "up",
			                  "trgcom",
			                  "cc";         /* in zephyr/dts/arm/st/l4/stm32l4.dtsi:304 */
			st,prescaler = < 0x0 >;         /* in zephyr/dts/arm/st/l4/stm32l4.dtsi:305 */
			status = "disabled";            /* in zephyr/dts/arm/st/l4/stm32l4.dtsi:306 */

			/* node '/soc/timers@40012c00/pwm' defined in zephyr/dts/arm/st/l4/stm32l4.dtsi:308 */
			pwm {
				compatible = "st,stm32-pwm"; /* in zephyr/dts/arm/st/l4/stm32l4.dtsi:309 */
				status = "disabled";         /* in zephyr/dts/arm/st/l4/stm32l4.dtsi:310 */
				#pwm-cells = < 0x3 >;        /* in zephyr/dts/arm/st/l4/stm32l4.dtsi:311 */
			};

			/* node '/soc/timers@40012c00/qdec' defined in zephyr/dts/arm/st/l4/stm32l4.dtsi:314 */
			qdec {
				compatible = "st,stm32-qdec";    /* in zephyr/dts/arm/st/l4/stm32l4.dtsi:315 */
				st,input-filter-level = < 0x0 >; /* in zephyr/dts/arm/st/l4/stm32l4.dtsi:316 */
				status = "disabled";             /* in zephyr/dts/arm/st/l4/stm32l4.dtsi:317 */
			};
		};

		/* node '/soc/timers@40000000' defined in zephyr/dts/arm/st/l4/stm32l4.dtsi:321 */
		timers2: timers@40000000 {
			compatible = "st,stm32-timers"; /* in zephyr/dts/arm/st/l4/stm32l4.dtsi:322 */
			reg = < 0x40000000 0x400 >;     /* in zephyr/dts/arm/st/l4/stm32l4.dtsi:323 */
			clocks = < &rcc 0x58 0x1 >,
			         < &rcc 0x8 0xff >;     /* in zephyr/dts/arm/st/l4/stm32l4.dtsi:324 */
			resets = < &rctl 0x700 >;       /* in zephyr/dts/arm/st/l4/stm32l4.dtsi:326 */
			interrupts = < 0x1c 0x0 >;      /* in zephyr/dts/arm/st/l4/stm32l4.dtsi:327 */
			interrupt-names = "global";     /* in zephyr/dts/arm/st/l4/stm32l4.dtsi:328 */
			st,prescaler = < 0x0 >;         /* in zephyr/dts/arm/st/l4/stm32l4.dtsi:329 */
			status = "okay";                /* in zephyr/boards/st/stm32l496g_disco/stm32l496g_disco.dts:132 */

			/* node '/soc/timers@40000000/pwm' defined in zephyr/dts/arm/st/l4/stm32l4.dtsi:332 */
			pwm2: pwm {
				compatible = "st,stm32-pwm";   /* in zephyr/dts/arm/st/l4/stm32l4.dtsi:333 */
				#pwm-cells = < 0x3 >;          /* in zephyr/dts/arm/st/l4/stm32l4.dtsi:335 */
				status = "okay";               /* in zephyr/boards/st/stm32l496g_disco/stm32l496g_disco.dts:135 */
				pinctrl-0 = < &tim2_ch1_pa0 >; /* in zephyr/boards/st/stm32l496g_disco/stm32l496g_disco.dts:136 */
				pinctrl-names = "default";     /* in zephyr/boards/st/stm32l496g_disco/stm32l496g_disco.dts:137 */
			};

			/* node '/soc/timers@40000000/counter' defined in zephyr/dts/arm/st/l4/stm32l4.dtsi:338 */
			counter {
				compatible = "st,stm32-counter"; /* in zephyr/dts/arm/st/l4/stm32l4.dtsi:339 */
				status = "disabled";             /* in zephyr/dts/arm/st/l4/stm32l4.dtsi:340 */
			};

			/* node '/soc/timers@40000000/qdec' defined in zephyr/dts/arm/st/l4/stm32l4.dtsi:343 */
			qdec {
				compatible = "st,stm32-qdec";    /* in zephyr/dts/arm/st/l4/stm32l4.dtsi:344 */
				st,input-filter-level = < 0x0 >; /* in zephyr/dts/arm/st/l4/stm32l4.dtsi:345 */
				status = "disabled";             /* in zephyr/dts/arm/st/l4/stm32l4.dtsi:346 */
			};
		};

		/* node '/soc/timers@40001000' defined in zephyr/dts/arm/st/l4/stm32l4.dtsi:350 */
		timers6: timers@40001000 {
			compatible = "st,stm32-timers"; /* in zephyr/dts/arm/st/l4/stm32l4.dtsi:351 */
			reg = < 0x40001000 0x400 >;     /* in zephyr/dts/arm/st/l4/stm32l4.dtsi:352 */
			clocks = < &rcc 0x58 0x10 >,
			         < &rcc 0x8 0xff >;     /* in zephyr/dts/arm/st/l4/stm32l4.dtsi:353 */
			resets = < &rctl 0x704 >;       /* in zephyr/dts/arm/st/l4/stm32l4.dtsi:355 */
			interrupts = < 0x36 0x0 >;      /* in zephyr/dts/arm/st/l4/stm32l4.dtsi:356 */
			interrupt-names = "global";     /* in zephyr/dts/arm/st/l4/stm32l4.dtsi:357 */
			st,prescaler = < 0x0 >;         /* in zephyr/dts/arm/st/l4/stm32l4.dtsi:358 */
			status = "disabled";            /* in zephyr/dts/arm/st/l4/stm32l4.dtsi:359 */

			/* node '/soc/timers@40001000/counter' defined in zephyr/dts/arm/st/l4/stm32l4.dtsi:361 */
			counter {
				compatible = "st,stm32-counter"; /* in zephyr/dts/arm/st/l4/stm32l4.dtsi:362 */
				status = "disabled";             /* in zephyr/dts/arm/st/l4/stm32l4.dtsi:363 */
			};
		};

		/* node '/soc/timers@40014000' defined in zephyr/dts/arm/st/l4/stm32l4.dtsi:367 */
		timers15: timers@40014000 {
			compatible = "st,stm32-timers"; /* in zephyr/dts/arm/st/l4/stm32l4.dtsi:368 */
			reg = < 0x40014000 0x400 >;     /* in zephyr/dts/arm/st/l4/stm32l4.dtsi:369 */
			clocks = < &rcc 0x60 0x10000 >,
			         < &rcc 0x9 0xff >;     /* in zephyr/dts/arm/st/l4/stm32l4.dtsi:370 */
			resets = < &rctl 0x810 >;       /* in zephyr/dts/arm/st/l4/stm32l4.dtsi:372 */
			interrupts = < 0x18 0x0 >;      /* in zephyr/dts/arm/st/l4/stm32l4.dtsi:373 */
			interrupt-names = "global";     /* in zephyr/dts/arm/st/l4/stm32l4.dtsi:374 */
			st,prescaler = < 0x0 >;         /* in zephyr/dts/arm/st/l4/stm32l4.dtsi:375 */
			status = "disabled";            /* in zephyr/dts/arm/st/l4/stm32l4.dtsi:376 */

			/* node '/soc/timers@40014000/pwm' defined in zephyr/dts/arm/st/l4/stm32l4.dtsi:378 */
			pwm {
				compatible = "st,stm32-pwm"; /* in zephyr/dts/arm/st/l4/stm32l4.dtsi:379 */
				status = "disabled";         /* in zephyr/dts/arm/st/l4/stm32l4.dtsi:380 */
				#pwm-cells = < 0x3 >;        /* in zephyr/dts/arm/st/l4/stm32l4.dtsi:381 */
			};

			/* node '/soc/timers@40014000/counter' defined in zephyr/dts/arm/st/l4/stm32l4.dtsi:384 */
			counter {
				compatible = "st,stm32-counter"; /* in zephyr/dts/arm/st/l4/stm32l4.dtsi:385 */
				status = "disabled";             /* in zephyr/dts/arm/st/l4/stm32l4.dtsi:386 */
			};
		};

		/* node '/soc/timers@40014400' defined in zephyr/dts/arm/st/l4/stm32l4.dtsi:390 */
		timers16: timers@40014400 {
			compatible = "st,stm32-timers"; /* in zephyr/dts/arm/st/l4/stm32l4.dtsi:391 */
			reg = < 0x40014400 0x400 >;     /* in zephyr/dts/arm/st/l4/stm32l4.dtsi:392 */
			clocks = < &rcc 0x60 0x20000 >,
			         < &rcc 0x9 0xff >;     /* in zephyr/dts/arm/st/l4/stm32l4.dtsi:393 */
			resets = < &rctl 0x811 >;       /* in zephyr/dts/arm/st/l4/stm32l4.dtsi:395 */
			interrupts = < 0x19 0x0 >;      /* in zephyr/dts/arm/st/l4/stm32l4.dtsi:396 */
			interrupt-names = "global";     /* in zephyr/dts/arm/st/l4/stm32l4.dtsi:397 */
			st,prescaler = < 0x0 >;         /* in zephyr/dts/arm/st/l4/stm32l4.dtsi:398 */
			status = "disabled";            /* in zephyr/dts/arm/st/l4/stm32l4.dtsi:399 */

			/* node '/soc/timers@40014400/pwm' defined in zephyr/dts/arm/st/l4/stm32l4.dtsi:401 */
			pwm {
				compatible = "st,stm32-pwm"; /* in zephyr/dts/arm/st/l4/stm32l4.dtsi:402 */
				status = "disabled";         /* in zephyr/dts/arm/st/l4/stm32l4.dtsi:403 */
				#pwm-cells = < 0x3 >;        /* in zephyr/dts/arm/st/l4/stm32l4.dtsi:404 */
			};

			/* node '/soc/timers@40014400/counter' defined in zephyr/dts/arm/st/l4/stm32l4.dtsi:407 */
			counter {
				compatible = "st,stm32-counter"; /* in zephyr/dts/arm/st/l4/stm32l4.dtsi:408 */
				status = "disabled";             /* in zephyr/dts/arm/st/l4/stm32l4.dtsi:409 */
			};
		};

		/* node '/soc/rtc@40002800' defined in zephyr/dts/arm/st/l4/stm32l4.dtsi:413 */
		rtc: rtc@40002800 {
			compatible = "st,stm32-rtc";       /* in zephyr/dts/arm/st/l4/stm32l4.dtsi:414 */
			reg = < 0x40002800 0x400 >;        /* in zephyr/dts/arm/st/l4/stm32l4.dtsi:415 */
			interrupts = < 0x29 0x0 >;         /* in zephyr/dts/arm/st/l4/stm32l4.dtsi:416 */
			prescaler = < 0x8000 >;            /* in zephyr/dts/arm/st/l4/stm32l4.dtsi:418 */
			alarms-count = < 0x2 >;            /* in zephyr/dts/arm/st/l4/stm32l4.dtsi:419 */
			alrm-exti-line = < 0x12 >;         /* in zephyr/dts/arm/st/l4/stm32l4.dtsi:420 */
			clocks = < &rcc 0x58 0x10000000 >,
			         < &rcc 0x3 0x2280090 >;   /* in zephyr/boards/st/stm32l496g_disco/stm32l496g_disco.dts:156 */
			status = "okay";                   /* in zephyr/boards/st/stm32l496g_disco/stm32l496g_disco.dts:158 */

			/* node '/soc/rtc@40002800/backup_regs' defined in zephyr/dts/arm/st/l4/stm32l471.dtsi:320 */
			bbram: backup_regs {
				compatible = "st,stm32-bbram"; /* in zephyr/dts/arm/st/l4/stm32l471.dtsi:321 */
				st,backup-regs = < 0x20 >;     /* in zephyr/dts/arm/st/l4/stm32l471.dtsi:322 */
				status = "disabled";           /* in zephyr/dts/arm/st/l4/stm32l471.dtsi:323 */
			};
		};

		/* node '/soc/adc@50040000' defined in zephyr/dts/arm/st/l4/stm32l4.dtsi:424 */
		adc1: adc@50040000 {
			compatible = "st,stm32-adc";                                /* in zephyr/dts/arm/st/l4/stm32l4.dtsi:425 */
			reg = < 0x50040000 0x100 >;                                 /* in zephyr/dts/arm/st/l4/stm32l4.dtsi:426 */
			clocks = < &rcc 0x4c 0x2000 >;                              /* in zephyr/dts/arm/st/l4/stm32l4.dtsi:427 */
			clock-names = "adcx";                                       /* in zephyr/dts/arm/st/l4/stm32l4.dtsi:428 */
			interrupts = < 0x12 0x0 >;                                  /* in zephyr/dts/arm/st/l4/stm32l4.dtsi:429 */
			#io-channel-cells = < 0x1 >;                                /* in zephyr/dts/arm/st/l4/stm32l4.dtsi:430 */
			resolutions = < 0x60630c 0x51630c 0x42630c 0x33630c >;      /* in zephyr/dts/arm/st/l4/stm32l4.dtsi:431 */
			sampling-times = < 0x3 0x7 0xd 0x19 0x30 0x5d 0xf8 0x281 >; /* in zephyr/dts/arm/st/l4/stm32l4.dtsi:435 */
			st,adc-sequencer = "programmable";                          /* in zephyr/dts/arm/st/l4/stm32l4.dtsi:436 */
			st,adc-oversampler = "minimal";                             /* in zephyr/dts/arm/st/l4/stm32l4.dtsi:437 */
			st,adc-internal-regulator = "startup-sw-delay";             /* in zephyr/dts/arm/st/l4/stm32l4.dtsi:438 */
			st,adc-has-deep-powerdown;                                  /* in zephyr/dts/arm/st/l4/stm32l4.dtsi:439 */
			st,adc-has-differential-support;                            /* in zephyr/dts/arm/st/l4/stm32l4.dtsi:440 */
			pinctrl-0 = < &adc1_in2_pc1 >;                              /* in zephyr/boards/st/stm32l496g_disco/stm32l496g_disco.dts:171 */
			pinctrl-names = "default";                                  /* in zephyr/boards/st/stm32l496g_disco/stm32l496g_disco.dts:172 */
			st,adc-clock-source = "SYNC";                               /* in zephyr/boards/st/stm32l496g_disco/stm32l496g_disco.dts:173 */
			st,adc-prescaler = < 0x4 >;                                 /* in zephyr/boards/st/stm32l496g_disco/stm32l496g_disco.dts:174 */
			status = "okay";                                            /* in zephyr/boards/st/stm32l496g_disco/stm32l496g_disco.dts:175 */
			phandle = < 0x28 >;                                         /* in zephyr/dts/arm/st/l4/stm32l4.dtsi:559 */
		};

		/* node '/soc/adc@50040100' defined in zephyr/dts/arm/st/l4/stm32l4.dtsi:444 */
		adc2: adc@50040100 {
			compatible = "st,stm32-adc";                                /* in zephyr/dts/arm/st/l4/stm32l4.dtsi:445 */
			reg = < 0x50040100 0x100 >;                                 /* in zephyr/dts/arm/st/l4/stm32l4.dtsi:446 */
			clocks = < &rcc 0x4c 0x2000 >;                              /* in zephyr/dts/arm/st/l4/stm32l4.dtsi:447 */
			clock-names = "adcx";                                       /* in zephyr/dts/arm/st/l4/stm32l4.dtsi:448 */
			interrupts = < 0x12 0x0 >;                                  /* in zephyr/dts/arm/st/l4/stm32l4.dtsi:449 */
			#io-channel-cells = < 0x1 >;                                /* in zephyr/dts/arm/st/l4/stm32l4.dtsi:450 */
			resolutions = < 0x60630c 0x51630c 0x42630c 0x33630c >;      /* in zephyr/dts/arm/st/l4/stm32l4.dtsi:451 */
			sampling-times = < 0x3 0x7 0xd 0x19 0x30 0x5d 0xf8 0x281 >; /* in zephyr/dts/arm/st/l4/stm32l4.dtsi:455 */
			st,adc-sequencer = "programmable";                          /* in zephyr/dts/arm/st/l4/stm32l4.dtsi:456 */
			st,adc-oversampler = "minimal";                             /* in zephyr/dts/arm/st/l4/stm32l4.dtsi:457 */
			st,adc-internal-regulator = "startup-sw-delay";             /* in zephyr/dts/arm/st/l4/stm32l4.dtsi:458 */
			st,adc-has-deep-powerdown;                                  /* in zephyr/dts/arm/st/l4/stm32l4.dtsi:459 */
			st,adc-has-differential-support;                            /* in zephyr/dts/arm/st/l4/stm32l4.dtsi:460 */
			status = "disabled";                                        /* in zephyr/dts/arm/st/l4/stm32l4.dtsi:461 */
		};

		/* node '/soc/dma@40020000' defined in zephyr/dts/arm/st/l4/stm32l4.dtsi:464 */
		dma1: dma@40020000 {
			compatible = "st,stm32-dma-v2";                                             /* in zephyr/dts/arm/st/l4/stm32l4.dtsi:465 */
			#dma-cells = < 0x3 >;                                                       /* in zephyr/dts/arm/st/l4/stm32l4.dtsi:466 */
			reg = < 0x40020000 0x400 >;                                                 /* in zephyr/dts/arm/st/l4/stm32l4.dtsi:467 */
			interrupts = < 0xb 0x0 0xc 0x0 0xd 0x0 0xe 0x0 0xf 0x0 0x10 0x0 0x11 0x0 >; /* in zephyr/dts/arm/st/l4/stm32l4.dtsi:468 */
			clocks = < &rcc 0x48 0x1 >;                                                 /* in zephyr/dts/arm/st/l4/stm32l4.dtsi:469 */
			dma-requests = < 0x7 >;                                                     /* in zephyr/dts/arm/st/l4/stm32l4.dtsi:470 */
			status = "disabled";                                                        /* in zephyr/dts/arm/st/l4/stm32l4.dtsi:471 */
		};

		/* node '/soc/dma@40020400' defined in zephyr/dts/arm/st/l4/stm32l4.dtsi:474 */
		dma2: dma@40020400 {
			compatible = "st,stm32-dma-v2";                                                  /* in zephyr/dts/arm/st/l4/stm32l4.dtsi:475 */
			#dma-cells = < 0x3 >;                                                            /* in zephyr/dts/arm/st/l4/stm32l4.dtsi:476 */
			reg = < 0x40020400 0x400 >;                                                      /* in zephyr/dts/arm/st/l4/stm32l4.dtsi:477 */
			interrupts = < 0x38 0x0 0x39 0x0 0x3a 0x0 0x3b 0x0 0x3c 0x0 0x44 0x0 0x45 0x0 >; /* in zephyr/dts/arm/st/l4/stm32l4.dtsi:478 */
			clocks = < &rcc 0x48 0x2 >;                                                      /* in zephyr/dts/arm/st/l4/stm32l4.dtsi:479 */
			dma-requests = < 0x7 >;                                                          /* in zephyr/dts/arm/st/l4/stm32l4.dtsi:480 */
			status = "okay";                                                                 /* in zephyr/boards/st/stm32l496g_disco/stm32l496g_disco.dts:194 */
			phandle = < 0x13 >;                                                              /* in zephyr/boards/st/stm32l496g_disco/stm32l496g_disco.dts:203 */
		};

		/* node '/soc/timers@40007c00' defined in zephyr/dts/arm/st/l4/stm32l4.dtsi:484 */
		lptim1: timers@40007c00 {
			compatible = "st,stm32-lptim";     /* in zephyr/dts/arm/st/l4/stm32l4.dtsi:485 */
			clocks = < &rcc 0x58 0x80000000 >; /* in zephyr/dts/arm/st/l4/stm32l4.dtsi:486 */
			#address-cells = < 0x1 >;          /* in zephyr/dts/arm/st/l4/stm32l4.dtsi:487 */
			#size-cells = < 0x0 >;             /* in zephyr/dts/arm/st/l4/stm32l4.dtsi:488 */
			reg = < 0x40007c00 0x400 >;        /* in zephyr/dts/arm/st/l4/stm32l4.dtsi:489 */
			interrupts = < 0x41 0x1 >;         /* in zephyr/dts/arm/st/l4/stm32l4.dtsi:490 */
			interrupt-names = "wakeup";        /* in zephyr/dts/arm/st/l4/stm32l4.dtsi:491 */
			status = "disabled";               /* in zephyr/dts/arm/st/l4/stm32l4.dtsi:492 */
		};

		/* node '/soc/timers@40009400' defined in zephyr/dts/arm/st/l4/stm32l4.dtsi:495 */
		lptim2: timers@40009400 {
			compatible = "st,stm32-lptim"; /* in zephyr/dts/arm/st/l4/stm32l4.dtsi:496 */
			#address-cells = < 0x1 >;      /* in zephyr/dts/arm/st/l4/stm32l4.dtsi:497 */
			#size-cells = < 0x0 >;         /* in zephyr/dts/arm/st/l4/stm32l4.dtsi:498 */
			reg = < 0x40009400 0x400 >;    /* in zephyr/dts/arm/st/l4/stm32l4.dtsi:499 */
			clocks = < &rcc 0x5c 0x20 >;   /* in zephyr/dts/arm/st/l4/stm32l4.dtsi:500 */
			interrupts = < 0x42 0x1 >;     /* in zephyr/dts/arm/st/l4/stm32l4.dtsi:501 */
			interrupt-names = "wakeup";    /* in zephyr/dts/arm/st/l4/stm32l4.dtsi:502 */
			status = "disabled";           /* in zephyr/dts/arm/st/l4/stm32l4.dtsi:503 */
		};

		/* node '/soc/rng@50060800' defined in zephyr/dts/arm/st/l4/stm32l4.dtsi:506 */
		rng: rng@50060800 {
			compatible = "st,stm32-rng";    /* in zephyr/dts/arm/st/l4/stm32l4.dtsi:507 */
			reg = < 0x50060800 0x400 >;     /* in zephyr/dts/arm/st/l4/stm32l4.dtsi:508 */
			interrupts = < 0x50 0x0 >;      /* in zephyr/dts/arm/st/l4/stm32l4.dtsi:509 */
			status = "disabled";            /* in zephyr/dts/arm/st/l4/stm32l4.dtsi:515 */
			clocks = < &rcc 0x4c 0x40000 >,
			         < &rcc 0x5 0x3a0088 >; /* in zephyr/dts/arm/st/l4/stm32l496.dtsi:23 */
		};

		/* node '/soc/power@40007000' defined in zephyr/dts/arm/st/l4/stm32l4.dtsi:518 */
		pwr: power@40007000 {
			compatible = "st,stm32-pwr"; /* in zephyr/dts/arm/st/l4/stm32l4.dtsi:519 */
			reg = < 0x40007000 0x400 >;  /* in zephyr/dts/arm/st/l4/stm32l4.dtsi:520 */
			status = "disabled";         /* in zephyr/dts/arm/st/l4/stm32l4.dtsi:521 */
			wkup-pins-nb = < 0x5 >;      /* in zephyr/dts/arm/st/l4/stm32l4.dtsi:523 */
			wkup-pins-pol;               /* in zephyr/dts/arm/st/l4/stm32l4.dtsi:524 */
			wkup-pins-pupd;              /* in zephyr/dts/arm/st/l4/stm32l4.dtsi:525 */
			#address-cells = < 0x1 >;    /* in zephyr/dts/arm/st/l4/stm32l4.dtsi:527 */
			#size-cells = < 0x0 >;       /* in zephyr/dts/arm/st/l4/stm32l4.dtsi:528 */

			/* node '/soc/power@40007000/wkup-pin@1' defined in zephyr/dts/arm/st/l4/stm32l4.dtsi:530 */
			wkup-pin@1 {
				reg = < 0x1 >; /* in zephyr/dts/arm/st/l4/stm32l4.dtsi:531 */
			};

			/* node '/soc/power@40007000/wkup-pin@2' defined in zephyr/dts/arm/st/l4/stm32l4.dtsi:534 */
			wkup-pin@2 {
				reg = < 0x2 >; /* in zephyr/dts/arm/st/l4/stm32l4.dtsi:535 */
			};

			/* node '/soc/power@40007000/wkup-pin@3' defined in zephyr/dts/arm/st/l4/stm32l4.dtsi:538 */
			wkup-pin@3 {
				reg = < 0x3 >; /* in zephyr/dts/arm/st/l4/stm32l4.dtsi:539 */
			};

			/* node '/soc/power@40007000/wkup-pin@4' defined in zephyr/dts/arm/st/l4/stm32l4.dtsi:542 */
			wkup-pin@4 {
				reg = < 0x4 >; /* in zephyr/dts/arm/st/l4/stm32l4.dtsi:543 */
			};

			/* node '/soc/power@40007000/wkup-pin@5' defined in zephyr/dts/arm/st/l4/stm32l4.dtsi:546 */
			wkup-pin@5 {
				reg = < 0x5 >; /* in zephyr/dts/arm/st/l4/stm32l4.dtsi:547 */
			};
		};

		/* node '/soc/sai1@40015404' defined in zephyr/dts/arm/st/l4/stm32l4_sai.dtsi:9 */
		sai1_a: sai1@40015404 {
			compatible = "st,stm32-sai";      /* in zephyr/dts/arm/st/l4/stm32l4_sai.dtsi:10 */
			#address-cells = < 0x1 >;         /* in zephyr/dts/arm/st/l4/stm32l4_sai.dtsi:11 */
			#size-cells = < 0x0 >;            /* in zephyr/dts/arm/st/l4/stm32l4_sai.dtsi:12 */
			reg = < 0x40015404 0x20 >;        /* in zephyr/dts/arm/st/l4/stm32l4_sai.dtsi:13 */
			clocks = < &rcc 0x60 0x200000 >,
			         < &rcc 0xd 0x360088 >;   /* in zephyr/dts/arm/st/l4/stm32l4_sai.dtsi:14 */
			dmas = < &dma2 0x1 0x1 0x22800 >; /* in zephyr/dts/arm/st/l4/stm32l4_sai.dtsi:16 */
			status = "disabled";              /* in zephyr/dts/arm/st/l4/stm32l4_sai.dtsi:18 */
		};

		/* node '/soc/sai1@40015424' defined in zephyr/dts/arm/st/l4/stm32l4_sai.dtsi:21 */
		sai1_b: sai1@40015424 {
			compatible = "st,stm32-sai";      /* in zephyr/dts/arm/st/l4/stm32l4_sai.dtsi:22 */
			#address-cells = < 0x1 >;         /* in zephyr/dts/arm/st/l4/stm32l4_sai.dtsi:23 */
			#size-cells = < 0x0 >;            /* in zephyr/dts/arm/st/l4/stm32l4_sai.dtsi:24 */
			reg = < 0x40015424 0x20 >;        /* in zephyr/dts/arm/st/l4/stm32l4_sai.dtsi:25 */
			clocks = < &rcc 0x60 0x200000 >,
			         < &rcc 0xd 0x360088 >;   /* in zephyr/dts/arm/st/l4/stm32l4_sai.dtsi:26 */
			dmas = < &dma2 0x2 0x1 0x22800 >; /* in zephyr/dts/arm/st/l4/stm32l4_sai.dtsi:28 */
			status = "disabled";              /* in zephyr/dts/arm/st/l4/stm32l4_sai.dtsi:30 */
		};

		/* node '/soc/serial@40004800' defined in zephyr/dts/arm/st/l4/stm32l471.dtsi:62 */
		usart3: serial@40004800 {
			compatible = "st,stm32-usart",
			             "st,stm32-uart";   /* in zephyr/dts/arm/st/l4/stm32l471.dtsi:63 */
			reg = < 0x40004800 0x400 >;     /* in zephyr/dts/arm/st/l4/stm32l471.dtsi:64 */
			clocks = < &rcc 0x58 0x40000 >; /* in zephyr/dts/arm/st/l4/stm32l471.dtsi:65 */
			resets = < &rctl 0x712 >;       /* in zephyr/dts/arm/st/l4/stm32l471.dtsi:66 */
			interrupts = < 0x27 0x0 >;      /* in zephyr/dts/arm/st/l4/stm32l471.dtsi:67 */
			status = "disabled";            /* in zephyr/dts/arm/st/l4/stm32l471.dtsi:68 */
		};

		/* node '/soc/serial@40004c00' defined in zephyr/dts/arm/st/l4/stm32l471.dtsi:71 */
		uart4: serial@40004c00 {
			compatible = "st,stm32-uart";   /* in zephyr/dts/arm/st/l4/stm32l471.dtsi:72 */
			reg = < 0x40004c00 0x400 >;     /* in zephyr/dts/arm/st/l4/stm32l471.dtsi:73 */
			clocks = < &rcc 0x58 0x80000 >; /* in zephyr/dts/arm/st/l4/stm32l471.dtsi:74 */
			resets = < &rctl 0x713 >;       /* in zephyr/dts/arm/st/l4/stm32l471.dtsi:75 */
			interrupts = < 0x34 0x0 >;      /* in zephyr/dts/arm/st/l4/stm32l471.dtsi:76 */
			status = "disabled";            /* in zephyr/dts/arm/st/l4/stm32l471.dtsi:77 */
		};

		/* node '/soc/serial@40005000' defined in zephyr/dts/arm/st/l4/stm32l471.dtsi:80 */
		uart5: serial@40005000 {
			compatible = "st,stm32-uart";    /* in zephyr/dts/arm/st/l4/stm32l471.dtsi:81 */
			reg = < 0x40005000 0x400 >;      /* in zephyr/dts/arm/st/l4/stm32l471.dtsi:82 */
			clocks = < &rcc 0x58 0x100000 >; /* in zephyr/dts/arm/st/l4/stm32l471.dtsi:83 */
			resets = < &rctl 0x714 >;        /* in zephyr/dts/arm/st/l4/stm32l471.dtsi:84 */
			interrupts = < 0x35 0x0 >;       /* in zephyr/dts/arm/st/l4/stm32l471.dtsi:85 */
			status = "disabled";             /* in zephyr/dts/arm/st/l4/stm32l471.dtsi:86 */
		};

		/* node '/soc/i2c@40005800' defined in zephyr/dts/arm/st/l4/stm32l471.dtsi:89 */
		i2c2: i2c@40005800 {
			compatible = "st,stm32-i2c-v2";  /* in zephyr/dts/arm/st/l4/stm32l471.dtsi:90 */
			clock-frequency = < 0x186a0 >;   /* in zephyr/dts/arm/st/l4/stm32l471.dtsi:91 */
			#address-cells = < 0x1 >;        /* in zephyr/dts/arm/st/l4/stm32l471.dtsi:92 */
			#size-cells = < 0x0 >;           /* in zephyr/dts/arm/st/l4/stm32l471.dtsi:93 */
			reg = < 0x40005800 0x400 >;      /* in zephyr/dts/arm/st/l4/stm32l471.dtsi:94 */
			clocks = < &rcc 0x58 0x400000 >; /* in zephyr/dts/arm/st/l4/stm32l471.dtsi:95 */
			interrupts = < 0x21 0x0 >,
			             < 0x22 0x0 >;       /* in zephyr/dts/arm/st/l4/stm32l471.dtsi:96 */
			interrupt-names = "event",
			                  "error";       /* in zephyr/dts/arm/st/l4/stm32l471.dtsi:97 */
			status = "disabled";             /* in zephyr/dts/arm/st/l4/stm32l471.dtsi:98 */
			phandle = < 0x2b >;              /* in zephyr/dts/arm/st/l4/stm32l471.dtsi:336 */
		};

		/* node '/soc/spi@40003800' defined in zephyr/dts/arm/st/l4/stm32l471.dtsi:101 */
		spi2: spi@40003800 {
			compatible = "st,stm32-spi-fifo",
			             "st,stm32-spi";      /* in zephyr/dts/arm/st/l4/stm32l471.dtsi:102 */
			#address-cells = < 0x1 >;         /* in zephyr/dts/arm/st/l4/stm32l471.dtsi:103 */
			#size-cells = < 0x0 >;            /* in zephyr/dts/arm/st/l4/stm32l471.dtsi:104 */
			reg = < 0x40003800 0x400 >;       /* in zephyr/dts/arm/st/l4/stm32l471.dtsi:105 */
			clocks = < &rcc 0x58 0x4000 >;    /* in zephyr/dts/arm/st/l4/stm32l471.dtsi:106 */
			interrupts = < 0x24 0x5 >;        /* in zephyr/dts/arm/st/l4/stm32l471.dtsi:107 */
			status = "disabled";              /* in zephyr/dts/arm/st/l4/stm32l471.dtsi:108 */
		};

		/* node '/soc/spi@40003c00' defined in zephyr/dts/arm/st/l4/stm32l471.dtsi:111 */
		spi3: spi@40003c00 {
			compatible = "st,stm32-spi-fifo",
			             "st,stm32-spi";      /* in zephyr/dts/arm/st/l4/stm32l471.dtsi:112 */
			#address-cells = < 0x1 >;         /* in zephyr/dts/arm/st/l4/stm32l471.dtsi:113 */
			#size-cells = < 0x0 >;            /* in zephyr/dts/arm/st/l4/stm32l471.dtsi:114 */
			reg = < 0x40003c00 0x400 >;       /* in zephyr/dts/arm/st/l4/stm32l471.dtsi:115 */
			clocks = < &rcc 0x58 0x8000 >;    /* in zephyr/dts/arm/st/l4/stm32l471.dtsi:116 */
			interrupts = < 0x33 0x5 >;        /* in zephyr/dts/arm/st/l4/stm32l471.dtsi:117 */
			status = "disabled";              /* in zephyr/dts/arm/st/l4/stm32l471.dtsi:118 */
		};

		/* node '/soc/timers@40000400' defined in zephyr/dts/arm/st/l4/stm32l471.dtsi:121 */
		timers3: timers@40000400 {
			compatible = "st,stm32-timers"; /* in zephyr/dts/arm/st/l4/stm32l471.dtsi:122 */
			reg = < 0x40000400 0x400 >;     /* in zephyr/dts/arm/st/l4/stm32l471.dtsi:123 */
			clocks = < &rcc 0x58 0x2 >,
			         < &rcc 0x8 0xff >;     /* in zephyr/dts/arm/st/l4/stm32l471.dtsi:124 */
			resets = < &rctl 0x701 >;       /* in zephyr/dts/arm/st/l4/stm32l471.dtsi:126 */
			interrupts = < 0x1d 0x0 >;      /* in zephyr/dts/arm/st/l4/stm32l471.dtsi:127 */
			interrupt-names = "global";     /* in zephyr/dts/arm/st/l4/stm32l471.dtsi:128 */
			st,prescaler = < 0x0 >;         /* in zephyr/dts/arm/st/l4/stm32l471.dtsi:129 */
			status = "disabled";            /* in zephyr/dts/arm/st/l4/stm32l471.dtsi:130 */

			/* node '/soc/timers@40000400/pwm' defined in zephyr/dts/arm/st/l4/stm32l471.dtsi:132 */
			pwm {
				compatible = "st,stm32-pwm"; /* in zephyr/dts/arm/st/l4/stm32l471.dtsi:133 */
				status = "disabled";         /* in zephyr/dts/arm/st/l4/stm32l471.dtsi:134 */
				#pwm-cells = < 0x3 >;        /* in zephyr/dts/arm/st/l4/stm32l471.dtsi:135 */
			};

			/* node '/soc/timers@40000400/counter' defined in zephyr/dts/arm/st/l4/stm32l471.dtsi:138 */
			counter {
				compatible = "st,stm32-counter"; /* in zephyr/dts/arm/st/l4/stm32l471.dtsi:139 */
				status = "disabled";             /* in zephyr/dts/arm/st/l4/stm32l471.dtsi:140 */
			};

			/* node '/soc/timers@40000400/qdec' defined in zephyr/dts/arm/st/l4/stm32l471.dtsi:143 */
			qdec {
				compatible = "st,stm32-qdec";    /* in zephyr/dts/arm/st/l4/stm32l471.dtsi:144 */
				st,input-filter-level = < 0x0 >; /* in zephyr/dts/arm/st/l4/stm32l471.dtsi:145 */
				status = "disabled";             /* in zephyr/dts/arm/st/l4/stm32l471.dtsi:146 */
			};
		};

		/* node '/soc/timers@40000800' defined in zephyr/dts/arm/st/l4/stm32l471.dtsi:150 */
		timers4: timers@40000800 {
			compatible = "st,stm32-timers"; /* in zephyr/dts/arm/st/l4/stm32l471.dtsi:151 */
			reg = < 0x40000800 0x400 >;     /* in zephyr/dts/arm/st/l4/stm32l471.dtsi:152 */
			clocks = < &rcc 0x58 0x4 >,
			         < &rcc 0x8 0xff >;     /* in zephyr/dts/arm/st/l4/stm32l471.dtsi:153 */
			resets = < &rctl 0x702 >;       /* in zephyr/dts/arm/st/l4/stm32l471.dtsi:155 */
			interrupts = < 0x1e 0x0 >;      /* in zephyr/dts/arm/st/l4/stm32l471.dtsi:156 */
			interrupt-names = "global";     /* in zephyr/dts/arm/st/l4/stm32l471.dtsi:157 */
			st,prescaler = < 0x0 >;         /* in zephyr/dts/arm/st/l4/stm32l471.dtsi:158 */
			status = "disabled";            /* in zephyr/dts/arm/st/l4/stm32l471.dtsi:159 */

			/* node '/soc/timers@40000800/pwm' defined in zephyr/dts/arm/st/l4/stm32l471.dtsi:161 */
			pwm {
				compatible = "st,stm32-pwm"; /* in zephyr/dts/arm/st/l4/stm32l471.dtsi:162 */
				status = "disabled";         /* in zephyr/dts/arm/st/l4/stm32l471.dtsi:163 */
				#pwm-cells = < 0x3 >;        /* in zephyr/dts/arm/st/l4/stm32l471.dtsi:164 */
			};

			/* node '/soc/timers@40000800/counter' defined in zephyr/dts/arm/st/l4/stm32l471.dtsi:167 */
			counter {
				compatible = "st,stm32-counter"; /* in zephyr/dts/arm/st/l4/stm32l471.dtsi:168 */
				status = "disabled";             /* in zephyr/dts/arm/st/l4/stm32l471.dtsi:169 */
			};

			/* node '/soc/timers@40000800/qdec' defined in zephyr/dts/arm/st/l4/stm32l471.dtsi:172 */
			qdec {
				compatible = "st,stm32-qdec";    /* in zephyr/dts/arm/st/l4/stm32l471.dtsi:173 */
				st,input-filter-level = < 0x0 >; /* in zephyr/dts/arm/st/l4/stm32l471.dtsi:174 */
				status = "disabled";             /* in zephyr/dts/arm/st/l4/stm32l471.dtsi:175 */
			};
		};

		/* node '/soc/timers@40000c00' defined in zephyr/dts/arm/st/l4/stm32l471.dtsi:179 */
		timers5: timers@40000c00 {
			compatible = "st,stm32-timers"; /* in zephyr/dts/arm/st/l4/stm32l471.dtsi:180 */
			reg = < 0x40000c00 0x400 >;     /* in zephyr/dts/arm/st/l4/stm32l471.dtsi:181 */
			clocks = < &rcc 0x58 0x8 >,
			         < &rcc 0x8 0xff >;     /* in zephyr/dts/arm/st/l4/stm32l471.dtsi:182 */
			resets = < &rctl 0x703 >;       /* in zephyr/dts/arm/st/l4/stm32l471.dtsi:184 */
			interrupts = < 0x32 0x0 >;      /* in zephyr/dts/arm/st/l4/stm32l471.dtsi:185 */
			interrupt-names = "global";     /* in zephyr/dts/arm/st/l4/stm32l471.dtsi:186 */
			st,prescaler = < 0x0 >;         /* in zephyr/dts/arm/st/l4/stm32l471.dtsi:187 */
			status = "disabled";            /* in zephyr/dts/arm/st/l4/stm32l471.dtsi:188 */

			/* node '/soc/timers@40000c00/pwm' defined in zephyr/dts/arm/st/l4/stm32l471.dtsi:190 */
			pwm {
				compatible = "st,stm32-pwm"; /* in zephyr/dts/arm/st/l4/stm32l471.dtsi:191 */
				status = "disabled";         /* in zephyr/dts/arm/st/l4/stm32l471.dtsi:192 */
				#pwm-cells = < 0x3 >;        /* in zephyr/dts/arm/st/l4/stm32l471.dtsi:193 */
			};

			/* node '/soc/timers@40000c00/counter' defined in zephyr/dts/arm/st/l4/stm32l471.dtsi:196 */
			counter {
				compatible = "st,stm32-counter"; /* in zephyr/dts/arm/st/l4/stm32l471.dtsi:197 */
				status = "disabled";             /* in zephyr/dts/arm/st/l4/stm32l471.dtsi:198 */
			};

			/* node '/soc/timers@40000c00/qdec' defined in zephyr/dts/arm/st/l4/stm32l471.dtsi:201 */
			qdec {
				compatible = "st,stm32-qdec";    /* in zephyr/dts/arm/st/l4/stm32l471.dtsi:202 */
				st,input-filter-level = < 0x0 >; /* in zephyr/dts/arm/st/l4/stm32l471.dtsi:203 */
				status = "disabled";             /* in zephyr/dts/arm/st/l4/stm32l471.dtsi:204 */
			};
		};

		/* node '/soc/timers@40001400' defined in zephyr/dts/arm/st/l4/stm32l471.dtsi:208 */
		timers7: timers@40001400 {
			compatible = "st,stm32-timers"; /* in zephyr/dts/arm/st/l4/stm32l471.dtsi:209 */
			reg = < 0x40001400 0x400 >;     /* in zephyr/dts/arm/st/l4/stm32l471.dtsi:210 */
			clocks = < &rcc 0x58 0x20 >,
			         < &rcc 0x8 0xff >;     /* in zephyr/dts/arm/st/l4/stm32l471.dtsi:211 */
			resets = < &rctl 0x705 >;       /* in zephyr/dts/arm/st/l4/stm32l471.dtsi:213 */
			interrupts = < 0x37 0x0 >;      /* in zephyr/dts/arm/st/l4/stm32l471.dtsi:214 */
			interrupt-names = "global";     /* in zephyr/dts/arm/st/l4/stm32l471.dtsi:215 */
			st,prescaler = < 0x0 >;         /* in zephyr/dts/arm/st/l4/stm32l471.dtsi:216 */
			status = "disabled";            /* in zephyr/dts/arm/st/l4/stm32l471.dtsi:217 */

			/* node '/soc/timers@40001400/counter' defined in zephyr/dts/arm/st/l4/stm32l471.dtsi:219 */
			counter {
				compatible = "st,stm32-counter"; /* in zephyr/dts/arm/st/l4/stm32l471.dtsi:220 */
				status = "disabled";             /* in zephyr/dts/arm/st/l4/stm32l471.dtsi:221 */
			};
		};

		/* node '/soc/timers@40013400' defined in zephyr/dts/arm/st/l4/stm32l471.dtsi:225 */
		timers8: timers@40013400 {
			compatible = "st,stm32-timers"; /* in zephyr/dts/arm/st/l4/stm32l471.dtsi:226 */
			reg = < 0x40013400 0x400 >;     /* in zephyr/dts/arm/st/l4/stm32l471.dtsi:227 */
			clocks = < &rcc 0x60 0x2000 >,
			         < &rcc 0x9 0xff >;     /* in zephyr/dts/arm/st/l4/stm32l471.dtsi:228 */
			resets = < &rctl 0x80d >;       /* in zephyr/dts/arm/st/l4/stm32l471.dtsi:230 */
			interrupts = < 0x2b 0x0 >,
			             < 0x2c 0x0 >,
			             < 0x2d 0x0 >,
			             < 0x2e 0x0 >;      /* in zephyr/dts/arm/st/l4/stm32l471.dtsi:231 */
			interrupt-names = "brk",
			                  "up",
			                  "trgcom",
			                  "cc";         /* in zephyr/dts/arm/st/l4/stm32l471.dtsi:232 */
			st,prescaler = < 0x0 >;         /* in zephyr/dts/arm/st/l4/stm32l471.dtsi:233 */
			status = "disabled";            /* in zephyr/dts/arm/st/l4/stm32l471.dtsi:234 */

			/* node '/soc/timers@40013400/pwm' defined in zephyr/dts/arm/st/l4/stm32l471.dtsi:236 */
			pwm {
				compatible = "st,stm32-pwm"; /* in zephyr/dts/arm/st/l4/stm32l471.dtsi:237 */
				status = "disabled";         /* in zephyr/dts/arm/st/l4/stm32l471.dtsi:238 */
				#pwm-cells = < 0x3 >;        /* in zephyr/dts/arm/st/l4/stm32l471.dtsi:239 */
			};

			/* node '/soc/timers@40013400/qdec' defined in zephyr/dts/arm/st/l4/stm32l471.dtsi:242 */
			qdec {
				compatible = "st,stm32-qdec";    /* in zephyr/dts/arm/st/l4/stm32l471.dtsi:243 */
				st,input-filter-level = < 0x0 >; /* in zephyr/dts/arm/st/l4/stm32l471.dtsi:244 */
				status = "disabled";             /* in zephyr/dts/arm/st/l4/stm32l471.dtsi:245 */
			};
		};

		/* node '/soc/timers@40014800' defined in zephyr/dts/arm/st/l4/stm32l471.dtsi:249 */
		timers17: timers@40014800 {
			compatible = "st,stm32-timers"; /* in zephyr/dts/arm/st/l4/stm32l471.dtsi:250 */
			reg = < 0x40014800 0x400 >;     /* in zephyr/dts/arm/st/l4/stm32l471.dtsi:251 */
			clocks = < &rcc 0x60 0x40000 >,
			         < &rcc 0x9 0xff >;     /* in zephyr/dts/arm/st/l4/stm32l471.dtsi:252 */
			resets = < &rctl 0x812 >;       /* in zephyr/dts/arm/st/l4/stm32l471.dtsi:254 */
			interrupts = < 0x1a 0x0 >;      /* in zephyr/dts/arm/st/l4/stm32l471.dtsi:255 */
			interrupt-names = "global";     /* in zephyr/dts/arm/st/l4/stm32l471.dtsi:256 */
			st,prescaler = < 0x0 >;         /* in zephyr/dts/arm/st/l4/stm32l471.dtsi:257 */
			status = "disabled";            /* in zephyr/dts/arm/st/l4/stm32l471.dtsi:258 */

			/* node '/soc/timers@40014800/pwm' defined in zephyr/dts/arm/st/l4/stm32l471.dtsi:260 */
			pwm {
				compatible = "st,stm32-pwm"; /* in zephyr/dts/arm/st/l4/stm32l471.dtsi:261 */
				status = "disabled";         /* in zephyr/dts/arm/st/l4/stm32l471.dtsi:262 */
				#pwm-cells = < 0x3 >;        /* in zephyr/dts/arm/st/l4/stm32l471.dtsi:263 */
			};

			/* node '/soc/timers@40014800/counter' defined in zephyr/dts/arm/st/l4/stm32l471.dtsi:266 */
			counter {
				compatible = "st,stm32-counter"; /* in zephyr/dts/arm/st/l4/stm32l471.dtsi:267 */
				status = "disabled";             /* in zephyr/dts/arm/st/l4/stm32l471.dtsi:268 */
			};
		};

		/* node '/soc/can@40006400' defined in zephyr/dts/arm/st/l4/stm32l471.dtsi:272 */
		can1: can@40006400 {
			compatible = "st,stm32-bxcan";    /* in zephyr/dts/arm/st/l4/stm32l471.dtsi:273 */
			reg = < 0x40006400 0x400 >;       /* in zephyr/dts/arm/st/l4/stm32l471.dtsi:274 */
			interrupts = < 0x13 0x0 >,
			             < 0x14 0x0 >,
			             < 0x15 0x0 >,
			             < 0x16 0x0 >;        /* in zephyr/dts/arm/st/l4/stm32l471.dtsi:275 */
			interrupt-names = "TX",
			                  "RX0",
			                  "RX1",
			                  "SCE";          /* in zephyr/dts/arm/st/l4/stm32l471.dtsi:276 */
			clocks = < &rcc 0x58 0x2000000 >; /* in zephyr/dts/arm/st/l4/stm32l471.dtsi:277 */
			status = "disabled";              /* in zephyr/dts/arm/st/l4/stm32l471.dtsi:278 */
		};

		/* node '/soc/sdmmc@40012800' defined in zephyr/dts/arm/st/l4/stm32l471.dtsi:281 */
		sdmmc1: sdmmc@40012800 {
			compatible = "st,stm32-sdmmc";                                                                                 /* in zephyr/dts/arm/st/l4/stm32l471.dtsi:282 */
			reg = < 0x40012800 0x400 >;                                                                                    /* in zephyr/dts/arm/st/l4/stm32l471.dtsi:283 */
			resets = < &rctl 0x80a >;                                                                                      /* in zephyr/dts/arm/st/l4/stm32l471.dtsi:286 */
			interrupts = < 0x31 0x0 >;                                                                                     /* in zephyr/dts/arm/st/l4/stm32l471.dtsi:287 */
			clocks = < &rcc 0x60 0x400 >,
			         < &rcc 0x5 0x3a0088 >;                                                                                /* in zephyr/dts/arm/st/l4/stm32l496.dtsi:68 */
			pinctrl-0 = < &sdmmc1_d0_pc8 &sdmmc1_d1_pc9 &sdmmc1_d2_pc10 &sdmmc1_d3_pc11 &sdmmc1_ck_pc12 &sdmmc1_cmd_pd2 >; /* in zephyr/boards/st/stm32l496g_disco/stm32l496g_disco.dts:162 */
			pinctrl-names = "default";                                                                                     /* in zephyr/boards/st/stm32l496g_disco/stm32l496g_disco.dts:165 */
			disk-name = "SD";                                                                                              /* in zephyr/boards/st/stm32l496g_disco/stm32l496g_disco.dts:166 */
			status = "okay";                                                                                               /* in zephyr/boards/st/stm32l496g_disco/stm32l496g_disco.dts:167 */
		};

		/* node '/soc/dac@40007400' defined in zephyr/dts/arm/st/l4/stm32l471.dtsi:291 */
		dac1: dac@40007400 {
			compatible = "st,stm32-dac";       /* in zephyr/dts/arm/st/l4/stm32l471.dtsi:292 */
			reg = < 0x40007400 0x400 >;        /* in zephyr/dts/arm/st/l4/stm32l471.dtsi:293 */
			clocks = < &rcc 0x58 0x20000000 >; /* in zephyr/dts/arm/st/l4/stm32l471.dtsi:294 */
			status = "disabled";               /* in zephyr/dts/arm/st/l4/stm32l471.dtsi:295 */
			#io-channel-cells = < 0x1 >;       /* in zephyr/dts/arm/st/l4/stm32l471.dtsi:296 */
		};

		/* node '/soc/adc@50040200' defined in zephyr/dts/arm/st/l4/stm32l471.dtsi:299 */
		adc3: adc@50040200 {
			compatible = "st,stm32-adc";                                /* in zephyr/dts/arm/st/l4/stm32l471.dtsi:300 */
			reg = < 0x50040200 0x100 >;                                 /* in zephyr/dts/arm/st/l4/stm32l471.dtsi:301 */
			clocks = < &rcc 0x4c 0x2000 >;                              /* in zephyr/dts/arm/st/l4/stm32l471.dtsi:302 */
			clock-names = "adcx";                                       /* in zephyr/dts/arm/st/l4/stm32l471.dtsi:303 */
			interrupts = < 0x2f 0x0 >;                                  /* in zephyr/dts/arm/st/l4/stm32l471.dtsi:304 */
			#io-channel-cells = < 0x1 >;                                /* in zephyr/dts/arm/st/l4/stm32l471.dtsi:305 */
			resolutions = < 0x60630c 0x51630c 0x42630c 0x33630c >;      /* in zephyr/dts/arm/st/l4/stm32l471.dtsi:306 */
			sampling-times = < 0x3 0x7 0xd 0x19 0x30 0x5d 0xf8 0x281 >; /* in zephyr/dts/arm/st/l4/stm32l471.dtsi:310 */
			st,adc-sequencer = "programmable";                          /* in zephyr/dts/arm/st/l4/stm32l471.dtsi:311 */
			st,adc-oversampler = "minimal";                             /* in zephyr/dts/arm/st/l4/stm32l471.dtsi:312 */
			st,adc-internal-regulator = "startup-sw-delay";             /* in zephyr/dts/arm/st/l4/stm32l471.dtsi:313 */
			st,adc-has-deep-powerdown;                                  /* in zephyr/dts/arm/st/l4/stm32l471.dtsi:314 */
			st,adc-has-differential-support;                            /* in zephyr/dts/arm/st/l4/stm32l471.dtsi:315 */
			status = "disabled";                                        /* in zephyr/dts/arm/st/l4/stm32l471.dtsi:316 */
		};

		/* node '/soc/otgfs@50000000' defined in zephyr/dts/arm/st/l4/stm32l475.dtsi:13 */
		usbotg_fs: zephyr_udc0: otgfs@50000000 {
			compatible = "st,stm32-otgfs";                                               /* in zephyr/dts/arm/st/l4/stm32l475.dtsi:14 */
			reg = < 0x50000000 0x40000 >;                                                /* in zephyr/dts/arm/st/l4/stm32l475.dtsi:15 */
			interrupts = < 0x43 0x0 >;                                                   /* in zephyr/dts/arm/st/l4/stm32l475.dtsi:16 */
			interrupt-names = "otgfs";                                                   /* in zephyr/dts/arm/st/l4/stm32l475.dtsi:17 */
			num-bidir-endpoints = < 0x6 >;                                               /* in zephyr/dts/arm/st/l4/stm32l475.dtsi:18 */
			ram-size = < 0x500 >;                                                        /* in zephyr/dts/arm/st/l4/stm32l475.dtsi:19 */
			maximum-speed = "full-speed";                                                /* in zephyr/dts/arm/st/l4/stm32l475.dtsi:20 */
			phys = < &otgfs_phy >;                                                       /* in zephyr/dts/arm/st/l4/stm32l475.dtsi:21 */
			clocks = < &rcc 0x4c 0x1000 >,
			         < &rcc 0x5 0x3a0088 >;                                              /* in zephyr/dts/arm/st/l4/stm32l496.dtsi:63 */
			pinctrl-0 = < &usb_otg_fs_dm_pa11 &usb_otg_fs_dp_pa12 &usb_otg_fs_id_pa10 >; /* in zephyr/boards/st/stm32l496g_disco/stm32l496g_disco.dts:179 */
			pinctrl-names = "default";                                                   /* in zephyr/boards/st/stm32l496g_disco/stm32l496g_disco.dts:181 */
			status = "okay";                                                             /* in zephyr/boards/st/stm32l496g_disco/stm32l496g_disco.dts:182 */
		};

		/* node '/soc/i2c@40008400' defined in zephyr/dts/arm/st/l4/stm32l496.dtsi:27 */
		i2c4: i2c@40008400 {
			compatible = "st,stm32-i2c-v2"; /* in zephyr/dts/arm/st/l4/stm32l496.dtsi:28 */
			clock-frequency = < 0x186a0 >;  /* in zephyr/dts/arm/st/l4/stm32l496.dtsi:29 */
			#address-cells = < 0x1 >;       /* in zephyr/dts/arm/st/l4/stm32l496.dtsi:30 */
			#size-cells = < 0x0 >;          /* in zephyr/dts/arm/st/l4/stm32l496.dtsi:31 */
			reg = < 0x40008400 0x400 >;     /* in zephyr/dts/arm/st/l4/stm32l496.dtsi:32 */
			clocks = < &rcc 0x5c 0x2 >;     /* in zephyr/dts/arm/st/l4/stm32l496.dtsi:33 */
			interrupts = < 0x53 0x0 >,
			             < 0x54 0x0 >;      /* in zephyr/dts/arm/st/l4/stm32l496.dtsi:34 */
			interrupt-names = "event",
			                  "error";      /* in zephyr/dts/arm/st/l4/stm32l496.dtsi:35 */
			status = "disabled";            /* in zephyr/dts/arm/st/l4/stm32l496.dtsi:36 */
			phandle = < 0x2c >;             /* in zephyr/dts/arm/st/l4/stm32l496.dtsi:81 */
		};

		/* node '/soc/can@40006800' defined in zephyr/dts/arm/st/l4/stm32l496.dtsi:52 */
		can2: can@40006800 {
			compatible = "st,stm32-bxcan";    /* in zephyr/dts/arm/st/l4/stm32l496.dtsi:53 */
			reg = < 0x40006800 0x400 >;       /* in zephyr/dts/arm/st/l4/stm32l496.dtsi:54 */
			interrupts = < 0x56 0x0 >,
			             < 0x57 0x0 >,
			             < 0x58 0x0 >,
			             < 0x59 0x0 >;        /* in zephyr/dts/arm/st/l4/stm32l496.dtsi:55 */
			interrupt-names = "TX",
			                  "RX0",
			                  "RX1",
			                  "SCE";          /* in zephyr/dts/arm/st/l4/stm32l496.dtsi:56 */
			clocks = < &rcc 0x58 0x4000000 >; /* in zephyr/dts/arm/st/l4/stm32l496.dtsi:57 */
			master-can-reg = < 0x40006400 >;  /* in zephyr/dts/arm/st/l4/stm32l496.dtsi:58 */
			status = "disabled";              /* in zephyr/dts/arm/st/l4/stm32l496.dtsi:59 */
		};
	};

	/* node '/cpus' defined in zephyr/dts/arm/st/l4/stm32l4.dtsi:30 */
	cpus {
		#address-cells = < 0x1 >; /* in zephyr/dts/arm/st/l4/stm32l4.dtsi:31 */
		#size-cells = < 0x0 >;    /* in zephyr/dts/arm/st/l4/stm32l4.dtsi:32 */

		/* node '/cpus/cpu@0' defined in zephyr/dts/arm/st/l4/stm32l4.dtsi:34 */
		cpu0: cpu@0 {
			device_type = "cpu";                         /* in zephyr/dts/arm/st/l4/stm32l4.dtsi:35 */
			compatible = "arm,cortex-m4f";               /* in zephyr/dts/arm/st/l4/stm32l4.dtsi:36 */
			reg = < 0x0 >;                               /* in zephyr/dts/arm/st/l4/stm32l4.dtsi:37 */
			cpu-power-states = < &stop0 &stop1 &stop2 >; /* in zephyr/dts/arm/st/l4/stm32l4.dtsi:38 */
		};

		/* node '/cpus/power-states' defined in zephyr/dts/arm/st/l4/stm32l4.dtsi:41 */
		power-states {

			/* node '/cpus/power-states/state0' defined in zephyr/dts/arm/st/l4/stm32l4.dtsi:42 */
			stop0: state0 {
				compatible = "zephyr,power-state";    /* in zephyr/dts/arm/st/l4/stm32l4.dtsi:43 */
				power-state-name = "suspend-to-idle"; /* in zephyr/dts/arm/st/l4/stm32l4.dtsi:44 */
				substate-id = < 0x1 >;                /* in zephyr/dts/arm/st/l4/stm32l4.dtsi:45 */
				min-residency-us = < 0x1f4 >;         /* in zephyr/dts/arm/st/l4/stm32l4.dtsi:46 */
				phandle = < 0x24 >;                   /* in zephyr/dts/arm/st/l4/stm32l4.dtsi:38 */
			};

			/* node '/cpus/power-states/state1' defined in zephyr/dts/arm/st/l4/stm32l4.dtsi:49 */
			stop1: state1 {
				compatible = "zephyr,power-state";    /* in zephyr/dts/arm/st/l4/stm32l4.dtsi:50 */
				power-state-name = "suspend-to-idle"; /* in zephyr/dts/arm/st/l4/stm32l4.dtsi:51 */
				substate-id = < 0x2 >;                /* in zephyr/dts/arm/st/l4/stm32l4.dtsi:52 */
				min-residency-us = < 0x2bc >;         /* in zephyr/dts/arm/st/l4/stm32l4.dtsi:53 */
				phandle = < 0x25 >;                   /* in zephyr/dts/arm/st/l4/stm32l4.dtsi:38 */
			};

			/* node '/cpus/power-states/state2' defined in zephyr/dts/arm/st/l4/stm32l4.dtsi:56 */
			stop2: state2 {
				compatible = "zephyr,power-state";    /* in zephyr/dts/arm/st/l4/stm32l4.dtsi:57 */
				power-state-name = "suspend-to-idle"; /* in zephyr/dts/arm/st/l4/stm32l4.dtsi:58 */
				substate-id = < 0x3 >;                /* in zephyr/dts/arm/st/l4/stm32l4.dtsi:59 */
				min-residency-us = < 0x3e8 >;         /* in zephyr/dts/arm/st/l4/stm32l4.dtsi:60 */
				phandle = < 0x26 >;                   /* in zephyr/dts/arm/st/l4/stm32l4.dtsi:38 */
			};
		};
	};

	/* node '/memory@20000000' defined in zephyr/dts/arm/st/l4/stm32l4.dtsi:65 */
	sram0: memory@20000000 {
		compatible = "zephyr,memory-region",
		             "mmio-sram";            /* in zephyr/dts/arm/st/l4/stm32l4.dtsi:66 */
		zephyr,memory-region = "SRAM0";      /* in zephyr/dts/arm/st/l4/stm32l4.dtsi:67 */
		reg = < 0x20000000 0x40000 >;        /* in zephyr/dts/arm/st/l4/stm32l496Xg.dtsi:10 */
	};

	/* node '/clocks' defined in zephyr/dts/arm/st/l4/stm32l4.dtsi:70 */
	clocks {

		/* node '/clocks/clk-hse' defined in zephyr/dts/arm/st/l4/stm32l4.dtsi:71 */
		clk_hse: clk-hse {
			#clock-cells = < 0x0 >;            /* in zephyr/dts/arm/st/l4/stm32l4.dtsi:72 */
			compatible = "st,stm32-hse-clock"; /* in zephyr/dts/arm/st/l4/stm32l4.dtsi:73 */
			status = "disabled";               /* in zephyr/dts/arm/st/l4/stm32l4.dtsi:74 */
		};

		/* node '/clocks/clk-hsi' defined in zephyr/dts/arm/st/l4/stm32l4.dtsi:77 */
		clk_hsi: clk-hsi {
			#clock-cells = < 0x0 >;         /* in zephyr/dts/arm/st/l4/stm32l4.dtsi:78 */
			compatible = "fixed-clock";     /* in zephyr/dts/arm/st/l4/stm32l4.dtsi:79 */
			clock-frequency = < 0xf42400 >; /* in zephyr/dts/arm/st/l4/stm32l4.dtsi:80 */
			status = "okay";                /* in zephyr/boards/st/stm32l496g_disco/stm32l496g_disco.dts:89 */
			phandle = < 0x27 >;             /* in zephyr/boards/st/stm32l496g_disco/stm32l496g_disco.dts:98 */
		};

		/* node '/clocks/clk-msi' defined in zephyr/dts/arm/st/l4/stm32l4.dtsi:84 */
		clk_msi: clk-msi {
			#clock-cells = < 0x0 >;            /* in zephyr/dts/arm/st/l4/stm32l4.dtsi:85 */
			compatible = "st,stm32-msi-clock"; /* in zephyr/dts/arm/st/l4/stm32l4.dtsi:86 */
			msi-range = < 0x6 >;               /* in zephyr/dts/arm/st/l4/stm32l4.dtsi:87 */
			status = "disabled";               /* in zephyr/dts/arm/st/l4/stm32l4.dtsi:88 */
		};

		/* node '/clocks/clk-lse' defined in zephyr/dts/arm/st/l4/stm32l4.dtsi:91 */
		clk_lse: clk-lse {
			#clock-cells = < 0x0 >;            /* in zephyr/dts/arm/st/l4/stm32l4.dtsi:92 */
			compatible = "st,stm32-lse-clock"; /* in zephyr/dts/arm/st/l4/stm32l4.dtsi:93 */
			clock-frequency = < 0x8000 >;      /* in zephyr/dts/arm/st/l4/stm32l4.dtsi:94 */
			driving-capability = < 0x0 >;      /* in zephyr/dts/arm/st/l4/stm32l4.dtsi:95 */
			status = "disabled";               /* in zephyr/dts/arm/st/l4/stm32l4.dtsi:96 */
		};

		/* node '/clocks/clk-lsi' defined in zephyr/dts/arm/st/l4/stm32l4.dtsi:99 */
		clk_lsi: clk-lsi {
			#clock-cells = < 0x0 >;       /* in zephyr/dts/arm/st/l4/stm32l4.dtsi:100 */
			compatible = "fixed-clock";   /* in zephyr/dts/arm/st/l4/stm32l4.dtsi:101 */
			clock-frequency = < 0x7d00 >; /* in zephyr/dts/arm/st/l4/stm32l4.dtsi:102 */
			status = "okay";              /* in zephyr/boards/st/stm32l496g_disco/stm32l496g_disco.dts:81 */
		};

		/* node '/clocks/pll' defined in zephyr/dts/arm/st/l4/stm32l4.dtsi:106 */
		pll: pll {
			#clock-cells = < 0x0 >;              /* in zephyr/dts/arm/st/l4/stm32l4.dtsi:107 */
			compatible = "st,stm32l4-pll-clock"; /* in zephyr/dts/arm/st/l4/stm32l4.dtsi:108 */
			div-m = < 0x1 >;                     /* in zephyr/boards/st/stm32l496g_disco/stm32l496g_disco.dts:93 */
			mul-n = < 0x14 >;                    /* in zephyr/boards/st/stm32l496g_disco/stm32l496g_disco.dts:94 */
			div-p = < 0x7 >;                     /* in zephyr/boards/st/stm32l496g_disco/stm32l496g_disco.dts:95 */
			div-q = < 0x2 >;                     /* in zephyr/boards/st/stm32l496g_disco/stm32l496g_disco.dts:96 */
			div-r = < 0x4 >;                     /* in zephyr/boards/st/stm32l496g_disco/stm32l496g_disco.dts:97 */
			clocks = < &clk_hsi >;               /* in zephyr/boards/st/stm32l496g_disco/stm32l496g_disco.dts:98 */
			status = "okay";                     /* in zephyr/boards/st/stm32l496g_disco/stm32l496g_disco.dts:99 */
			phandle = < 0x3 >;                   /* in zephyr/boards/st/stm32l496g_disco/stm32l496g_disco.dts:103 */
		};

		/* node '/clocks/pllsai1' defined in zephyr/dts/arm/st/l4/stm32l4.dtsi:112 */
		pllsai1: pllsai1 {
			#clock-cells = < 0x0 >;                 /* in zephyr/dts/arm/st/l4/stm32l4.dtsi:113 */
			compatible = "st,stm32l4-pllsai-clock"; /* in zephyr/dts/arm/st/l4/stm32l4.dtsi:114 */
			status = "disabled";                    /* in zephyr/dts/arm/st/l4/stm32l4.dtsi:115 */
		};

		/* node '/clocks/pllsai2' defined in zephyr/dts/arm/st/l4/stm32l471.dtsi:18 */
		pllsai2: pllsai2 {
			#clock-cells = < 0x0 >;                 /* in zephyr/dts/arm/st/l4/stm32l471.dtsi:19 */
			compatible = "st,stm32l4-pllsai-clock"; /* in zephyr/dts/arm/st/l4/stm32l471.dtsi:20 */
			status = "disabled";                    /* in zephyr/dts/arm/st/l4/stm32l471.dtsi:21 */
		};

		/* node '/clocks/clk-hsi48' defined in zephyr/dts/arm/st/l4/stm32l496.dtsi:11 */
		clk_hsi48: clk-hsi48 {
			#clock-cells = < 0x0 >;          /* in zephyr/dts/arm/st/l4/stm32l496.dtsi:12 */
			compatible = "fixed-clock";      /* in zephyr/dts/arm/st/l4/stm32l496.dtsi:13 */
			clock-frequency = < 0x2dc6c00 >; /* in zephyr/dts/arm/st/l4/stm32l496.dtsi:14 */
			status = "okay";                 /* in zephyr/boards/st/stm32l496g_disco/stm32l496g_disco.dts:85 */
		};
	};

	/* node '/mcos' defined in zephyr/dts/arm/st/l4/stm32l4.dtsi:119 */
	mcos {

		/* node '/mcos/mco1' defined in zephyr/dts/arm/st/l4/stm32l4.dtsi:120 */
		mco1: mco1 {
			compatible = "st,stm32-clock-mco"; /* in zephyr/dts/arm/st/l4/stm32l4.dtsi:121 */
			status = "disabled";               /* in zephyr/dts/arm/st/l4/stm32l4.dtsi:122 */
		};
	};

	/* node '/dietemp' defined in zephyr/dts/arm/st/l4/stm32l4.dtsi:552 */
	die_temp: dietemp {
		compatible = "st,stm32-temp-cal"; /* in zephyr/dts/arm/st/l4/stm32l4.dtsi:553 */
		ts-cal1-addr = < 0x1fff75a8 >;    /* in zephyr/dts/arm/st/l4/stm32l4.dtsi:554 */
		ts-cal2-addr = < 0x1fff75ca >;    /* in zephyr/dts/arm/st/l4/stm32l4.dtsi:555 */
		ts-cal1-temp = < 0x1e >;          /* in zephyr/dts/arm/st/l4/stm32l4.dtsi:556 */
		ts-cal-vrefanalog = < 0xbb8 >;    /* in zephyr/dts/arm/st/l4/stm32l4.dtsi:558 */
		io-channels = < &adc1 0x11 >;     /* in zephyr/dts/arm/st/l4/stm32l4.dtsi:559 */
		status = "disabled";              /* in zephyr/dts/arm/st/l4/stm32l4.dtsi:560 */
		ts-cal2-temp = < 0x82 >;          /* in zephyr/dts/arm/st/l4/stm32l496.dtsi:74 */
	};

	/* node '/vref' defined in zephyr/dts/arm/st/l4/stm32l4.dtsi:563 */
	vref: vref {
		compatible = "st,stm32-vref";      /* in zephyr/dts/arm/st/l4/stm32l4.dtsi:564 */
		vrefint-cal-addr = < 0x1fff75aa >; /* in zephyr/dts/arm/st/l4/stm32l4.dtsi:565 */
		vrefint-cal-mv = < 0xbb8 >;        /* in zephyr/dts/arm/st/l4/stm32l4.dtsi:566 */
		io-channels = < &adc1 0x0 >;       /* in zephyr/dts/arm/st/l4/stm32l4.dtsi:567 */
		status = "okay";                   /* in zephyr/boards/st/stm32l496g_disco/stm32l496g_disco.dts:186 */
	};

	/* node '/vbat' defined in zephyr/dts/arm/st/l4/stm32l4.dtsi:571 */
	vbat: vbat {
		compatible = "st,stm32-vbat"; /* in zephyr/dts/arm/st/l4/stm32l4.dtsi:572 */
		ratio = < 0x3 >;              /* in zephyr/dts/arm/st/l4/stm32l4.dtsi:573 */
		io-channels = < &adc1 0x12 >; /* in zephyr/dts/arm/st/l4/stm32l4.dtsi:574 */
		status = "okay";              /* in zephyr/boards/st/stm32l496g_disco/stm32l496g_disco.dts:190 */
	};

	/* node '/smbus1' defined in zephyr/dts/arm/st/l4/stm32l4.dtsi:578 */
	smbus1: smbus1 {
		compatible = "st,stm32-smbus"; /* in zephyr/dts/arm/st/l4/stm32l4.dtsi:579 */
		#address-cells = < 0x1 >;      /* in zephyr/dts/arm/st/l4/stm32l4.dtsi:580 */
		#size-cells = < 0x0 >;         /* in zephyr/dts/arm/st/l4/stm32l4.dtsi:581 */
		i2c = < &i2c1 >;               /* in zephyr/dts/arm/st/l4/stm32l4.dtsi:582 */
		status = "disabled";           /* in zephyr/dts/arm/st/l4/stm32l4.dtsi:583 */
	};

	/* node '/smbus3' defined in zephyr/dts/arm/st/l4/stm32l4.dtsi:586 */
	smbus3: smbus3 {
		compatible = "st,stm32-smbus"; /* in zephyr/dts/arm/st/l4/stm32l4.dtsi:587 */
		#address-cells = < 0x1 >;      /* in zephyr/dts/arm/st/l4/stm32l4.dtsi:588 */
		#size-cells = < 0x0 >;         /* in zephyr/dts/arm/st/l4/stm32l4.dtsi:589 */
		i2c = < &i2c3 >;               /* in zephyr/dts/arm/st/l4/stm32l4.dtsi:590 */
		status = "disabled";           /* in zephyr/dts/arm/st/l4/stm32l4.dtsi:591 */
	};

	/* node '/memory@10000000' defined in zephyr/dts/arm/st/l4/stm32l471.dtsi:12 */
	sram1: memory@10000000 {
		compatible = "zephyr,memory-region",
		             "mmio-sram";            /* in zephyr/dts/arm/st/l4/stm32l471.dtsi:13 */
		zephyr,memory-region = "SRAM1";      /* in zephyr/dts/arm/st/l4/stm32l471.dtsi:14 */
		reg = < 0x10000000 0x10000 >;        /* in zephyr/dts/arm/st/l4/stm32l496Xg.dtsi:14 */
	};

	/* node '/smbus2' defined in zephyr/dts/arm/st/l4/stm32l471.dtsi:332 */
	smbus2: smbus2 {
		compatible = "st,stm32-smbus"; /* in zephyr/dts/arm/st/l4/stm32l471.dtsi:333 */
		#address-cells = < 0x1 >;      /* in zephyr/dts/arm/st/l4/stm32l471.dtsi:334 */
		#size-cells = < 0x0 >;         /* in zephyr/dts/arm/st/l4/stm32l471.dtsi:335 */
		i2c = < &i2c2 >;               /* in zephyr/dts/arm/st/l4/stm32l471.dtsi:336 */
		status = "disabled";           /* in zephyr/dts/arm/st/l4/stm32l471.dtsi:337 */
	};

	/* node '/otgfs_phy' defined in zephyr/dts/arm/st/l4/stm32l475.dtsi:28 */
	otgfs_phy: otgfs_phy {
		compatible = "usb-nop-xceiv"; /* in zephyr/dts/arm/st/l4/stm32l475.dtsi:29 */
		#phy-cells = < 0x0 >;         /* in zephyr/dts/arm/st/l4/stm32l475.dtsi:30 */
		phandle = < 0x20 >;           /* in zephyr/dts/arm/st/l4/stm32l475.dtsi:21 */
	};

	/* node '/smbus4' defined in zephyr/dts/arm/st/l4/stm32l496.dtsi:77 */
	smbus4: smbus4 {
		compatible = "st,stm32-smbus"; /* in zephyr/dts/arm/st/l4/stm32l496.dtsi:78 */
		#address-cells = < 0x1 >;      /* in zephyr/dts/arm/st/l4/stm32l496.dtsi:79 */
		#size-cells = < 0x0 >;         /* in zephyr/dts/arm/st/l4/stm32l496.dtsi:80 */
		i2c = < &i2c4 >;               /* in zephyr/dts/arm/st/l4/stm32l496.dtsi:81 */
		status = "disabled";           /* in zephyr/dts/arm/st/l4/stm32l496.dtsi:82 */
	};

	/* node '/connector' defined in zephyr/boards/st/stm32l496g_disco/arduino_r3_connector.dtsi:10 */
	arduino_header: connector {
		compatible = "arduino-header-r3";          /* in zephyr/boards/st/stm32l496g_disco/arduino_r3_connector.dtsi:11 */
		#gpio-cells = < 0x2 >;                     /* in zephyr/boards/st/stm32l496g_disco/arduino_r3_connector.dtsi:12 */
		gpio-map-mask = < 0xffffffff 0xffffffc0 >; /* in zephyr/boards/st/stm32l496g_disco/arduino_r3_connector.dtsi:13 */
		gpio-map-pass-thru = < 0x0 0x3f >;         /* in zephyr/boards/st/stm32l496g_disco/arduino_r3_connector.dtsi:14 */
		gpio-map = < 0x0 0x0 &gpioc 0x4 0x0 >,
		           < 0x1 0x0 &gpioc 0x1 0x0 >,
		           < 0x2 0x0 &gpioc 0x3 0x0 >,
		           < 0x3 0x0 &gpiof 0xa 0x0 >,
		           < 0x4 0x0 &gpioa 0x1 0x0 >,
		           < 0x5 0x0 &gpioc 0x0 0x0 >,
		           < 0x6 0x0 &gpiog 0x8 0x0 >,
		           < 0x7 0x0 &gpiog 0x7 0x0 >,
		           < 0x8 0x0 &gpiog 0xd 0x0 >,
		           < 0x9 0x0 &gpioh 0xf 0x0 >,
		           < 0xa 0x0 &gpioi 0xb 0x0 >,
		           < 0xb 0x0 &gpiob 0x9 0x0 >,
		           < 0xc 0x0 &gpioi 0x6 0x0 >,
		           < 0xd 0x0 &gpiog 0x6 0x0 >,
		           < 0xe 0x0 &gpiog 0xf 0x0 >,
		           < 0xf 0x0 &gpioh 0xd 0x0 >,
		           < 0x10 0x0 &gpioa 0xf 0x0 >,
		           < 0x11 0x0 &gpiob 0x5 0x0 >,
		           < 0x12 0x0 &gpiob 0x4 0x0 >,
		           < 0x13 0x0 &gpioa 0x5 0x0 >,
		           < 0x14 0x0 &gpiob 0x7 0x0 >,
		           < 0x15 0x0 &gpiob 0x8 0x0 >;    /* in zephyr/boards/st/stm32l496g_disco/arduino_r3_connector.dtsi:15 */
	};

	/* node '/leds' defined in zephyr/boards/st/stm32l496g_disco/stm32l496g_disco.dts:25 */
	leds {
		compatible = "gpio-leds"; /* in zephyr/boards/st/stm32l496g_disco/stm32l496g_disco.dts:26 */

		/* node '/leds/led_2' defined in zephyr/boards/st/stm32l496g_disco/stm32l496g_disco.dts:28 */
		green_led_2: led_2 {
			gpios = < &gpiob 0xd 0x0 >; /* in zephyr/boards/st/stm32l496g_disco/stm32l496g_disco.dts:29 */
			label = "User LD2";         /* in zephyr/boards/st/stm32l496g_disco/stm32l496g_disco.dts:30 */
		};
	};

	/* node '/gpio_keys' defined in zephyr/boards/st/stm32l496g_disco/stm32l496g_disco.dts:34 */
	gpio_keys {
		compatible = "gpio-keys"; /* in zephyr/boards/st/stm32l496g_disco/stm32l496g_disco.dts:35 */

		/* node '/gpio_keys/joystick_select' defined in zephyr/boards/st/stm32l496g_disco/stm32l496g_disco.dts:37 */
		joy_sel: joystick_select {
			label = "joystick select";   /* in zephyr/boards/st/stm32l496g_disco/stm32l496g_disco.dts:38 */
			gpios = < &gpioc 0xd 0x20 >; /* in zephyr/boards/st/stm32l496g_disco/stm32l496g_disco.dts:39 */
			zephyr,code = < 0x1c >;      /* in zephyr/boards/st/stm32l496g_disco/stm32l496g_disco.dts:40 */
		};

		/* node '/gpio_keys/joystick_down' defined in zephyr/boards/st/stm32l496g_disco/stm32l496g_disco.dts:43 */
		joy_down: joystick_down {
			label = "joystick down";     /* in zephyr/boards/st/stm32l496g_disco/stm32l496g_disco.dts:44 */
			gpios = < &gpioi 0xa 0x20 >; /* in zephyr/boards/st/stm32l496g_disco/stm32l496g_disco.dts:45 */
			zephyr,code = < 0x6c >;      /* in zephyr/boards/st/stm32l496g_disco/stm32l496g_disco.dts:46 */
		};

		/* node '/gpio_keys/joystick_up' defined in zephyr/boards/st/stm32l496g_disco/stm32l496g_disco.dts:49 */
		joy_up: joystick_up {
			label = "joystick up";       /* in zephyr/boards/st/stm32l496g_disco/stm32l496g_disco.dts:50 */
			gpios = < &gpioi 0x8 0x20 >; /* in zephyr/boards/st/stm32l496g_disco/stm32l496g_disco.dts:51 */
			zephyr,code = < 0x67 >;      /* in zephyr/boards/st/stm32l496g_disco/stm32l496g_disco.dts:52 */
		};

		/* node '/gpio_keys/joystick_left' defined in zephyr/boards/st/stm32l496g_disco/stm32l496g_disco.dts:55 */
		joy_left: joystick_left {
			label = "joystick left";     /* in zephyr/boards/st/stm32l496g_disco/stm32l496g_disco.dts:56 */
			gpios = < &gpioi 0x9 0x20 >; /* in zephyr/boards/st/stm32l496g_disco/stm32l496g_disco.dts:57 */
			zephyr,code = < 0x69 >;      /* in zephyr/boards/st/stm32l496g_disco/stm32l496g_disco.dts:58 */
		};

		/* node '/gpio_keys/joystick_right' defined in zephyr/boards/st/stm32l496g_disco/stm32l496g_disco.dts:61 */
		joy_right: joystick_right {
			label = "joystick right";    /* in zephyr/boards/st/stm32l496g_disco/stm32l496g_disco.dts:62 */
			gpios = < &gpiof 0xb 0x20 >; /* in zephyr/boards/st/stm32l496g_disco/stm32l496g_disco.dts:63 */
			zephyr,code = < 0x6a >;      /* in zephyr/boards/st/stm32l496g_disco/stm32l496g_disco.dts:64 */
		};
	};
};
